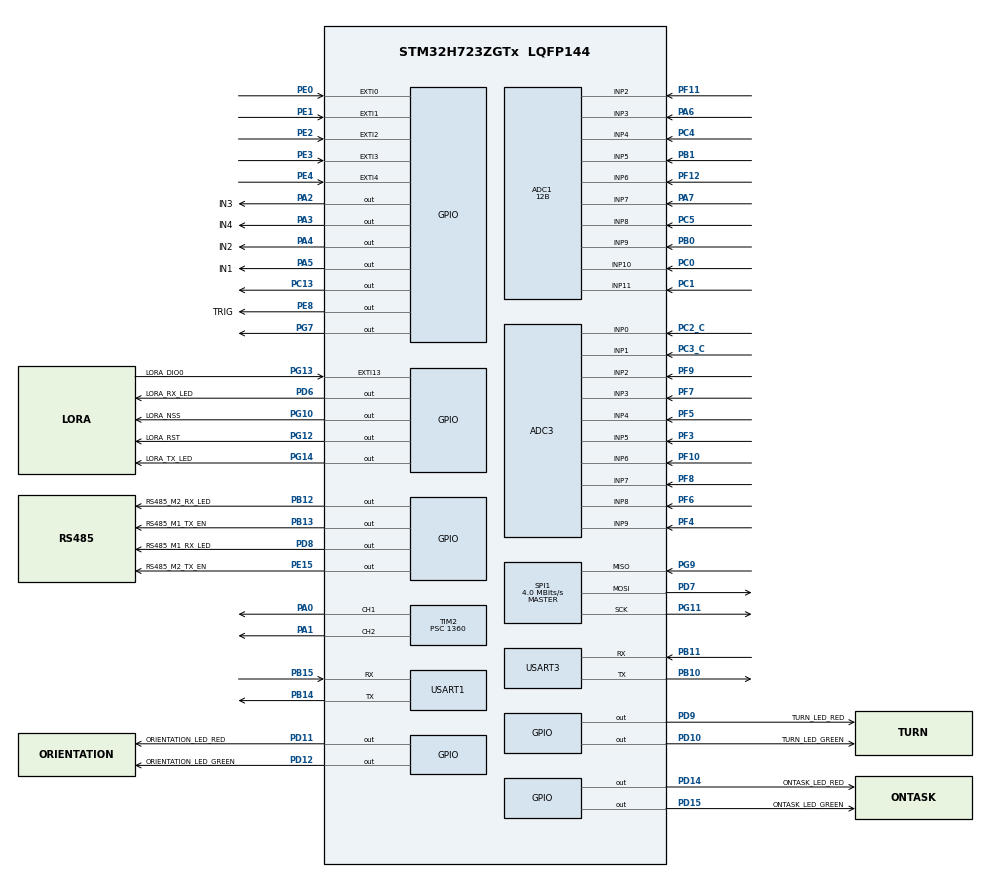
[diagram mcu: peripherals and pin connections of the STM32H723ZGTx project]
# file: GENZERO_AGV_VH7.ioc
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ADC1.Channel-0\#ChannelRegularConversion=ADC_CHANNEL_11
ADC1.Channel-1\#ChannelRegularConversion=ADC_CHANNEL_10
ADC1.Channel-2\#ChannelRegularConversion=ADC_CHANNEL_9
ADC1.Channel-3\#ChannelRegularConversion=ADC_CHANNEL_8
ADC1.Channel-4\#ChannelRegularConversion=ADC_CHANNEL_7
ADC1.Channel-5\#ChannelRegularConversion=ADC_CHANNEL_6
ADC1.Channel-6\#ChannelRegularConversion=ADC_CHANNEL_5
ADC1.Channel-7\#ChannelRegularConversion=ADC_CHANNEL_4
ADC1.Channel-8\#ChannelRegularConversion=ADC_CHANNEL_3
ADC1.Channel-9\#ChannelRegularConversion=ADC_CHANNEL_2
ADC1.ClockPrescaler=ADC_CLOCK_ASYNC_DIV1
ADC1.ClockPrescalerADC3=ADC_CLOCK_ASYNC_DIV1
ADC1.ContinuousConvMode=ENABLE
ADC1.ConversionDataManagement=ADC_CONVERSIONDATA_DMA_CIRCULAR
ADC1.EOCSelection=ADC_EOC_SINGLE_CONV
ADC1.NbrOfConversion=10
ADC1.NbrOfConversionFlag=1
ADC1.OffsetNumber-0\#ChannelRegularConversion=ADC_OFFSET_NONE
ADC1.OffsetNumber-1\#ChannelRegularConversion=ADC_OFFSET_NONE
ADC1.OffsetNumber-2\#ChannelRegularConversion=ADC_OFFSET_NONE
ADC1.OffsetNumber-3\#ChannelRegularConversion=ADC_OFFSET_NONE
ADC1.OffsetNumber-4\#ChannelRegularConversion=ADC_OFFSET_NONE
ADC1.OffsetNumber-5\#ChannelRegularConversion=ADC_OFFSET_NONE
ADC1.OffsetNumber-6\#ChannelRegularConversion=ADC_OFFSET_NONE
ADC1.OffsetNumber-7\#ChannelRegularConversion=ADC_OFFSET_NONE
ADC1.OffsetNumber-8\#ChannelRegularConversion=ADC_OFFSET_NONE
ADC1.OffsetNumber-9\#ChannelRegularConversion=ADC_OFFSET_NONE
ADC1.OffsetSignedSaturation-0\#ChannelRegularConversion=DISABLE
ADC1.Overrun=ADC_OVR_DATA_OVERWRITTEN
ADC1.Rank-0\#ChannelRegularConversion=1
ADC1.Rank-1\#ChannelRegularConversion=2
ADC1.Rank-2\#ChannelRegularConversion=3
ADC1.Rank-3\#ChannelRegularConversion=4
ADC1.Rank-4\#ChannelRegularConversion=5
ADC1.Rank-5\#ChannelRegularConversion=6
ADC1.Rank-6\#ChannelRegularConversion=7
ADC1.Rank-7\#ChannelRegularConversion=8
ADC1.Rank-8\#ChannelRegularConversion=9
ADC1.Rank-9\#ChannelRegularConversion=10
ADC1.Resolution=ADC_RESOLUTION_12B
ADC1.SamplingTime-0\#ChannelRegularConversion=ADC_SAMPLETIME_64CYCLES_5
ADC1.SamplingTime-1\#ChannelRegularConversion=ADC_SAMPLETIME_64CYCLES_5
ADC1.SamplingTime-2\#ChannelRegularConversion=ADC_SAMPLETIME_64CYCLES_5
ADC1.SamplingTime-3\#ChannelRegularConversion=ADC_SAMPLETIME_64CYCLES_5
ADC1.SamplingTime-4\#ChannelRegularConversion=ADC_SAMPLETIME_64CYCLES_5
ADC1.SamplingTime-5\#ChannelRegularConversion=ADC_SAMPLETIME_64CYCLES_5
ADC1.SamplingTime-6\#ChannelRegularConversion=ADC_SAMPLETIME_64CYCLES_5
ADC1.SamplingTime-7\#ChannelRegularConversion=ADC_SAMPLETIME_64CYCLES_5
ADC1.SamplingTime-8\#ChannelRegularConversion=ADC_SAMPLETIME_64CYCLES_5
ADC1.SamplingTime-9\#ChannelRegularConversion=ADC_SAMPLETIME_64CYCLES_5
ADC1.master=1
ADC3.Channel-0\#ChannelRegularConversion=ADC_CHANNEL_9
ADC3.Channel-1\#ChannelRegularConversion=ADC_CHANNEL_8
ADC3.Channel-2\#ChannelRegularConversion=ADC_CHANNEL_7
ADC3.Channel-3\#ChannelRegularConversion=ADC_CHANNEL_6
ADC3.Channel-4\#ChannelRegularConversion=ADC_CHANNEL_5
ADC3.Channel-5\#ChannelRegularConversion=ADC_CHANNEL_4
ADC3.Channel-6\#ChannelRegularConversion=ADC_CHANNEL_3
ADC3.Channel-7\#ChannelRegularConversion=ADC_CHANNEL_2
ADC3.Channel-8\#ChannelRegularConversion=ADC_CHANNEL_1
ADC3.Channel-9\#ChannelRegularConversion=ADC_CHANNEL_0
ADC3.ClockPrescaler=ADC_CLOCK_ASYNC_DIV1
ADC3.ClockPrescalerADC3=ADC_CLOCK_ASYNC_DIV1
ADC3.ContinuousConvMode=ENABLE
ADC3.ConversionDataManagement=ADC_CONVERSIONDATA_DMA_CIRCULAR
ADC3.DMAContinuousRequests=ENABLE
ADC3.EOCSelection=ADC_EOC_SINGLE_CONV
ADC3.NbrOfConversion=10
ADC3.NbrOfConversionFlag=1
ADC3.OffsetNumber-0\#ChannelRegularConversion=ADC_OFFSET_NONE
ADC3.OffsetNumber-1\#ChannelRegularConversion=ADC_OFFSET_NONE
ADC3.OffsetNumber-2\#ChannelRegularConversion=ADC_OFFSET_NONE
ADC3.OffsetNumber-3\#ChannelRegularConversion=ADC_OFFSET_NONE
ADC3.OffsetNumber-4\#ChannelRegularConversion=ADC_OFFSET_NONE
ADC3.OffsetNumber-5\#ChannelRegularConversion=ADC_OFFSET_NONE
ADC3.OffsetNumber-6\#ChannelRegularConversion=ADC_OFFSET_NONE
ADC3.OffsetNumber-7\#ChannelRegularConversion=ADC_OFFSET_NONE
ADC3.OffsetNumber-8\#ChannelRegularConversion=ADC_OFFSET_NONE
ADC3.OffsetNumber-9\#ChannelRegularConversion=ADC_OFFSET_NONE
ADC3.OffsetSign-0\#ChannelRegularConversion=ADC3_OFFSET_SIGN_NEGATIVE
ADC3.OffsetSign-1\#ChannelRegularConversion=ADC3_OFFSET_SIGN_NEGATIVE
ADC3.OffsetSign-2\#ChannelRegularConversion=ADC3_OFFSET_SIGN_NEGATIVE
ADC3.OffsetSign-3\#ChannelRegularConversion=ADC3_OFFSET_SIGN_NEGATIVE
ADC3.OffsetSign-4\#ChannelRegularConversion=ADC3_OFFSET_SIGN_NEGATIVE
ADC3.OffsetSign-5\#ChannelRegularConversion=ADC3_OFFSET_SIGN_NEGATIVE
ADC3.OffsetSign-6\#ChannelRegularConversion=ADC3_OFFSET_SIGN_NEGATIVE
ADC3.OffsetSign-7\#ChannelRegularConversion=ADC3_OFFSET_SIGN_NEGATIVE
ADC3.OffsetSign-8\#ChannelRegularConversion=ADC3_OFFSET_SIGN_NEGATIVE
ADC3.OffsetSign-9\#ChannelRegularConversion=ADC3_OFFSET_SIGN_NEGATIVE
ADC3.Overrun=ADC_OVR_DATA_OVERWRITTEN
ADC3.Rank-0\#ChannelRegularConversion=1
ADC3.Rank-1\#ChannelRegularConversion=2
ADC3.Rank-2\#ChannelRegularConversion=3
ADC3.Rank-3\#ChannelRegularConversion=4
ADC3.Rank-4\#ChannelRegularConversion=5
ADC3.Rank-5\#ChannelRegularConversion=6
ADC3.Rank-6\#ChannelRegularConversion=7
ADC3.Rank-7\#ChannelRegularConversion=8
ADC3.Rank-8\#ChannelRegularConversion=9
ADC3.Rank-9\#ChannelRegularConversion=10
ADC3.SamplingTime-0\#ChannelRegularConversion=ADC3_SAMPLETIME_92CYCLES_5
ADC3.SamplingTime-1\#ChannelRegularConversion=ADC3_SAMPLETIME_92CYCLES_5
ADC3.SamplingTime-2\#ChannelRegularConversion=ADC3_SAMPLETIME_92CYCLES_5
ADC3.SamplingTime-3\#ChannelRegularConversion=ADC3_SAMPLETIME_92CYCLES_5
ADC3.SamplingTime-4\#ChannelRegularConversion=ADC3_SAMPLETIME_92CYCLES_5
ADC3.SamplingTime-5\#ChannelRegularConversion=ADC3_SAMPLETIME_92CYCLES_5
ADC3.SamplingTime-6\#ChannelRegularConversion=ADC3_SAMPLETIME_92CYCLES_5
ADC3.SamplingTime-7\#ChannelRegularConversion=ADC3_SAMPLETIME_92CYCLES_5
ADC3.SamplingTime-8\#ChannelRegularConversion=ADC3_SAMPLETIME_92CYCLES_5
ADC3.SamplingTime-9\#ChannelRegularConversion=ADC3_SAMPLETIME_92CYCLES_5
Dma.ADC1.0.Direction=DMA_PERIPH_TO_MEMORY
Dma.ADC1.0.EventEnable=DISABLE
Dma.ADC1.0.FIFOMode=DMA_FIFOMODE_DISABLE
Dma.ADC1.0.Instance=DMA1_Stream0
Dma.ADC1.0.MemDataAlignment=DMA_MDATAALIGN_HALFWORD
Dma.ADC1.0.MemInc=DMA_MINC_ENABLE
Dma.ADC1.0.Mode=DMA_CIRCULAR
Dma.ADC1.0.PeriphDataAlignment=DMA_PDATAALIGN_HALFWORD
Dma.ADC1.0.PeriphInc=DMA_PINC_DISABLE
Dma.ADC1.0.Polarity=HAL_DMAMUX_REQ_GEN_RISING
Dma.ADC1.0.Priority=DMA_PRIORITY_HIGH
Dma.ADC1.0.RequestNumber=1
Dma.ADC1.0.SignalID=NONE
Dma.ADC1.0.SyncEnable=DISABLE
Dma.ADC1.0.SyncPolarity=HAL_DMAMUX_SYNC_NO_EVENT
Dma.ADC1.0.SyncRequestNumber=1
Dma.ADC1.0.SyncSignalID=NONE
Dma.ADC3.1.Direction=DMA_PERIPH_TO_MEMORY
Dma.ADC3.1.EventEnable=DISABLE
Dma.ADC3.1.FIFOMode=DMA_FIFOMODE_DISABLE
Dma.ADC3.1.Instance=DMA1_Stream1
Dma.ADC3.1.MemDataAlignment=DMA_MDATAALIGN_HALFWORD
Dma.ADC3.1.MemInc=DMA_MINC_ENABLE
Dma.ADC3.1.Mode=DMA_CIRCULAR
Dma.ADC3.1.PeriphDataAlignment=DMA_PDATAALIGN_HALFWORD
Dma.ADC3.1.PeriphInc=DMA_PINC_DISABLE
Dma.ADC3.1.Polarity=HAL_DMAMUX_REQ_GEN_RISING
Dma.ADC3.1.Priority=DMA_PRIORITY_HIGH
Dma.ADC3.1.RequestNumber=1
Dma.ADC3.1.SignalID=NONE
Dma.ADC3.1.SyncEnable=DISABLE
Dma.ADC3.1.SyncPolarity=HAL_DMAMUX_SYNC_NO_EVENT
Dma.ADC3.1.SyncRequestNumber=1
Dma.ADC3.1.SyncSignalID=NONE
Dma.Request0=ADC1
Dma.Request1=ADC3
Mcu.Family=STM32H7
Mcu.Name=STM32H723ZGTx
Mcu.Package=LQFP144
NVIC.ADC3_IRQn=true\:0\:0\:false\:false\:true\:true\:true\:true
NVIC.ADC_IRQn=true\:0\:0\:false\:false\:true\:true\:true\:true
NVIC.DMA1_Stream0_IRQn=true\:0\:0\:false\:false\:true\:false\:true\:true
NVIC.DMA1_Stream1_IRQn=true\:0\:0\:false\:false\:true\:false\:true\:true
NVIC.EXTI0_IRQn=true\:0\:0\:false\:false\:true\:true\:true\:true
NVIC.EXTI15_10_IRQn=true\:0\:0\:false\:false\:true\:true\:true\:true
NVIC.EXTI1_IRQn=true\:0\:0\:false\:false\:true\:true\:true\:true
NVIC.EXTI2_IRQn=true\:0\:0\:false\:false\:true\:true\:true\:true
NVIC.EXTI3_IRQn=true\:0\:0\:false\:false\:true\:true\:true\:true
NVIC.PriorityGroup=NVIC_PRIORITYGROUP_4
NVIC.TIM2_IRQn=true\:0\:0\:false\:false\:true\:true\:true\:true
NVIC.TIM3_IRQn=true\:0\:0\:false\:false\:true\:true\:true\:true
NVIC.TIM4_IRQn=true\:0\:0\:false\:false\:true\:true\:true\:true
NVIC.USART1_IRQn=true\:0\:0\:true\:false\:true\:true\:true\:true
NVIC.USART3_IRQn=true\:0\:0\:false\:false\:true\:true\:true\:true
PA0.Signal=S_TIM2_CH1_ETR
PA1.Signal=S_TIM2_CH2
PA2.GPIO_Label=IN3
PA2.Signal=GPIO_Output
PA3.GPIO_Label=IN4
PA3.Signal=GPIO_Output
PA4.GPIO_Label=IN2
PA4.Signal=GPIO_Output
PA5.GPIO_Label=IN1
PA5.Signal=GPIO_Output
PA6.Signal=ADCx_INP3
PA7.Signal=ADCx_INP7
PB0.Signal=ADCx_INP9
PB1.Signal=ADCx_INP5
PB10.Mode=Asynchronous
PB10.Signal=USART3_TX
PB11.Mode=Asynchronous
PB11.Signal=USART3_RX
PB12.GPIO_Label=RS485_M2_RX_LED
PB12.Signal=GPIO_Output
PB13.GPIO_Label=RS485_M1_TX_EN
PB13.GPIO_Speed=GPIO_SPEED_FREQ_HIGH
PB13.Signal=GPIO_Output
PB14.GPIO_Speed=GPIO_SPEED_FREQ_VERY_HIGH
PB14.Mode=Asynchronous
PB14.Signal=USART1_TX
PB15.GPIO_Speed=GPIO_SPEED_FREQ_VERY_HIGH
PB15.Mode=Asynchronous
PB15.Signal=USART1_RX
PC0.Signal=ADCx_INP10
PC1.Signal=ADCx_INP11
PC13.Signal=GPIO_Output
PC2_C.Mode=IN0-Single-Ended
PC2_C.Signal=ADC3_INP0
PC3_C.Mode=IN1-Single-Ended
PC3_C.Signal=ADC3_INP1
PC4.Signal=ADCx_INP4
PC5.Signal=ADCx_INP8
PD10.GPIO_Label=TURN_LED_GREEN
PD10.Signal=GPIO_Output
PD11.GPIO_Label=ORIENTATION_LED_RED
PD11.Signal=GPIO_Output
PD12.GPIO_Label=ORIENTATION_LED_GREEN
PD12.Signal=GPIO_Output
PD14.GPIO_Label=ONTASK_LED_RED
PD14.Signal=GPIO_Output
PD15.GPIO_Label=ONTASK_LED_GREEN
PD15.Signal=GPIO_Output
PD6.GPIO_Label=LORA_RX_LED
PD6.PinState=GPIO_PIN_SET
PD6.Signal=GPIO_Output
PD7.Mode=Full_Duplex_Master
PD7.Signal=SPI1_MOSI
PD8.GPIO_Label=RS485_M1_RX_LED
PD8.Signal=GPIO_Output
PD9.GPIO_Label=TURN_LED_RED
PD9.Signal=GPIO_Output
PE0.GPIO_ModeDefaultEXTI=GPIO_MODE_IT_FALLING
PE0.Signal=GPXTI0
PE1.GPIO_ModeDefaultEXTI=GPIO_MODE_IT_FALLING
PE1.Signal=GPXTI1
PE15.GPIO_Label=RS485_M2_TX_EN
PE15.GPIO_Speed=GPIO_SPEED_FREQ_HIGH
PE15.Signal=GPIO_Output
PE2.GPIO_ModeDefaultEXTI=GPIO_MODE_IT_FALLING
PE2.Signal=GPXTI2
PE3.GPIO_ModeDefaultEXTI=GPIO_MODE_IT_FALLING
PE3.Signal=GPXTI3
PE4.GPIO_ModeDefaultEXTI=GPIO_MODE_IT_FALLING
PE4.Signal=GPXTI4
PE8.GPIO_Label=TRIG
PE8.GPIO_PuPd=GPIO_PULLDOWN
PE8.GPIO_Speed=GPIO_SPEED_FREQ_HIGH
PE8.Signal=GPIO_Output
PF10.Mode=IN6-Single-Ended
PF10.Signal=ADC3_INP6
PF11.Mode=IN2-Single-Ended
PF11.Signal=ADC1_INP2
PF12.Mode=IN6-Single-Ended
PF12.Signal=ADC1_INP6
PF3.Mode=IN5-Single-Ended
PF3.Signal=ADC3_INP5
PF4.Mode=IN9-Single-Ended
PF4.Signal=ADC3_INP9
PF5.Mode=IN4-Single-Ended
PF5.Signal=ADC3_INP4
PF6.Mode=IN8-Single-Ended
PF6.Signal=ADC3_INP8
PF7.Mode=IN3-Single-Ended
PF7.Signal=ADC3_INP3
PF8.Mode=IN7-Single-Ended
PF8.Signal=ADC3_INP7
PF9.Mode=IN2-Single-Ended
PF9.Signal=ADC3_INP2
PG10.GPIO_Label=LORA_NSS
PG10.PinState=GPIO_PIN_SET
PG10.Signal=GPIO_Output
PG11.Mode=Full_Duplex_Master
PG11.Signal=SPI1_SCK
PG12.GPIO_Label=LORA_RST
PG12.PinState=GPIO_PIN_SET
PG12.Signal=GPIO_Output
PG13.GPIO_Label=LORA_DIO0
PG13.Signal=GPXTI13
PG14.GPIO_Label=LORA_TX_LED
PG14.Signal=GPIO_Output
PG7.Signal=GPIO_Output
PG9.Mode=Full_Duplex_Master
PG9.Signal=SPI1_MISO
PH0-OSC_IN.Mode=HSE-External-Oscillator
PH0-OSC_IN.Signal=RCC_OSC_IN
PH1-OSC_OUT.Mode=HSE-External-Oscillator
PH1-OSC_OUT.Signal=RCC_OSC_OUT
ProjectManager.HeapSize=0x200
ProjectManager.StackSize=0x400
ProjectManager.TargetToolchain=STM32CubeIDE
RCC.ADCFreq_Value=96000671.38671875
RCC.APB1Freq_Value=137500000
RCC.APB2Freq_Value=137500000
RCC.APB3Freq_Value=137500000
RCC.APB4Freq_Value=137500000
RCC.CortexFreq_Value=550000000
RCC.D1PPRE=RCC_APB3_DIV2
RCC.D2PPRE1=RCC_APB1_DIV2
RCC.D2PPRE2=RCC_APB2_DIV2
RCC.D3PPRE=RCC_APB4_DIV2
RCC.DIVM1=2
RCC.DIVM2=2
RCC.DIVN1=44
RCC.DIVN2=15
RCC.DIVP1=1
RCC.DIVQ1=3
RCC.HCLKFreq_Value=275000000
RCC.HPRE=RCC_HCLK_DIV2
RCC.PLL2FRACN=2950
RCC.PLL3FRACN=0
RCC.PLLFRACN=0
RCC.PLLSourceVirtual=RCC_PLLSOURCE_HSE
RCC.SPI123CLockSelection=RCC_SPI123CLKSOURCE_CLKP
RCC.SYSCLKFreq_VALUE=550000000
RCC.SYSCLKSource=RCC_SYSCLKSOURCE_PLLCLK
RCC.USBFreq_Value=183333333.33333334
SH.ADCx_INP10.0=ADC1_INP10,IN10-Single-Ended
SH.ADCx_INP11.0=ADC1_INP11,IN11-Single-Ended
SH.ADCx_INP3.0=ADC1_INP3,IN3-Single-Ended
SH.ADCx_INP4.0=ADC1_INP4,IN4-Single-Ended
SH.ADCx_INP5.0=ADC1_INP5,IN5-Single-Ended
SH.ADCx_INP7.0=ADC1_INP7,IN7-Single-Ended
SH.ADCx_INP8.0=ADC1_INP8,IN8-Single-Ended
SH.ADCx_INP9.0=ADC1_INP9,IN9-Single-Ended
SH.S_TIM2_CH1_ETR.0=TIM2_CH1,PWM Generation1 CH1
SH.S_TIM2_CH2.0=TIM2_CH2,PWM Generation2 CH2
SPI1.BaudRatePrescaler=SPI_BAUDRATEPRESCALER_16
SPI1.CalculateBaudRate=4.0 MBits/s
SPI1.DataSize=SPI_DATASIZE_8BIT
SPI1.Direction=SPI_DIRECTION_2LINES
SPI1.Mode=SPI_MODE_MASTER
SPI1.VirtualType=VM_MASTER
TIM2.AutoReloadPreload=TIM_AUTORELOAD_PRELOAD_ENABLE
TIM2.Channel-PWM\ Generation1\ CH1=TIM_CHANNEL_1
TIM2.Channel-PWM\ Generation2\ CH2=TIM_CHANNEL_2
TIM2.ClockDivision=TIM_CLOCKDIVISION_DIV1
TIM2.OC1Preload_PWM=DISABLE
TIM2.OC2Preload_PWM=DISABLE
TIM2.OCFastMode_PWM-PWM\ Generation1\ CH1=TIM_OCFAST_DISABLE
TIM2.OCFastMode_PWM-PWM\ Generation2\ CH2=TIM_OCFAST_DISABLE
TIM2.Period=100
TIM2.Prescaler=1360
TIM3.AutoReloadPreload=TIM_AUTORELOAD_PRELOAD_ENABLE
TIM3.Period=55000-1
TIM3.Prescaler=500-1
TIM4.AutoReloadPreload=TIM_AUTORELOAD_PRELOAD_ENABLE
TIM4.Period=55000-1
TIM4.Prescaler=500-1
USART1.ClockPrescaler=PRESCALER_DIV1
USART1.VirtualMode-Asynchronous=VM_ASYNC
USART3.VirtualMode-Asynchronous=VM_ASYNC
VP_MEMORYMAP_VS_MEMORYMAP.Mode=CurAppReg
VP_TIM3_VS_ClockSourceINT.Mode=Internal
VP_TIM4_VS_ClockSourceINT.Mode=Internal
board=custom

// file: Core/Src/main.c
/* USER CODE BEGIN Header */
/**
  ******************************************************************************
  * @file           : main.c
  * @brief          : Main program body
  ******************************************************************************
  * @attention
  *
  * Copyright (c) 2024 STMicroelectronics.
  * All rights reserved.
  *
  * This software is licensed under terms that can be found in the LICENSE file
  * in the root directory of this software component.
  * If no LICENSE file comes with this software, it is provided AS-IS.
  *
  ******************************************************************************

	GIT BRANCH: TEST TWO

  */
/* USER CODE END Header */
#include "main.h"

/* USER CODE BEGIN Includes */

#include "modbus_crc.h"
#include "line_sensor.h"
#include "LoRa.h"
#include "rs485_driver.h"

/* USER CODE END Includes */

ADC_HandleTypeDef hadc1;
ADC_HandleTypeDef hadc3;
DMA_HandleTypeDef hdma_adc1;
DMA_HandleTypeDef hdma_adc3;

SPI_HandleTypeDef hspi1;

TIM_HandleTypeDef htim2;
TIM_HandleTypeDef htim3;
TIM_HandleTypeDef htim4;

UART_HandleTypeDef huart1;
UART_HandleTypeDef huart3;

/* USER CODE BEGIN PV */

// #### RS485 ####

uint8_t rs485_m1_RxData[16];
uint8_t rs485_m1_TxData[8];

uint8_t rs485_m2_RxData[16];
uint8_t rs485_m2_TxData[8];

uint8_t rs485_m1_isbusy = 0;
uint8_t rs485_m2_isbusy = 0;

uint16_t rs485_m1_FailCheck = 0;
uint16_t rs485_m2_FailCheck = 0;

uint16_t rs485_m1_last_FailCheck = 0;
uint16_t rs485_m2_last_FailCheck = 0;

uint8_t rs485_m1_connectivity = 0;
uint8_t rs485_m2_connectivity = 0;

uint16_t rs485_exc_time = 0;
uint32_t rs485_time1 = 0;
uint32_t rs485_time2 = 0;

rs485_driver m1_driver;
rs485_driver m2_driver;

uint8_t time_t1 = 0;
uint8_t time_t2 = 0;

const uint16_t mid_point = 4500;

// #### END RS485 ####

// -o-o-o-o-o-o-o-o-o-o-o-o-o-o-o-o-o-

// #### LINE SENSOR VARIABLES ####

#define line_sensor_front_total_channel 10
#define line_sensor_back_total_channel 10

#define max_rs485_speed 100

int line_sensor_front_read_line_old_value;
int line_sensor_back_read_line_old_value;

volatile uint16_t line_sensor_front_values_dma[line_sensor_front_total_channel];
volatile uint16_t line_sensor_back_values_dma[line_sensor_back_total_channel];

volatile uint16_t line_sensor_front_values_calibrated[line_sensor_front_total_channel];
volatile uint16_t line_sensor_back_values_calibrated[line_sensor_back_total_channel];

volatile uint8_t line_sensor_front_on_line_left_number, line_sensor_front_on_line_middle_number, line_sensor_front_on_line_right_number;
volatile uint8_t line_sensor_front_on_line_total_number;

volatile uint8_t line_sensor_back_on_line_left_number, line_sensor_back_on_line_middle_number, line_sensor_back_on_line_right_number;
volatile uint8_t line_sensor_back_on_line_total_number;

uint16_t line_sensor_front_max_sensor_vales[line_sensor_front_total_channel] = {4095, 4095, 4095, 4095, 4095, 4095, 4095, 4095, 4095, 4095};
uint16_t line_sensor_front_min_sensor_vales[line_sensor_front_total_channel] = {560, 550, 600, 540, 500, 530, 500, 500, 500, 500};

uint16_t line_sensor_back_max_sensor_vales[line_sensor_back_total_channel] = {4095, 4095, 4095, 4095, 4095, 4095, 2800, 4095, 2800, 4095};
uint16_t line_sensor_back_min_sensor_vales[line_sensor_back_total_channel] = {750, 800, 700, 700, 700, 700, 500, 700, 550, 600};

const uint8_t line_sensor_front_channel_number = sizeof(line_sensor_front_values_dma)/sizeof(line_sensor_front_values_dma[0]);
const uint8_t line_sensor_back_channel_number = sizeof(line_sensor_back_values_dma)/sizeof(line_sensor_back_values_dma[0]);

volatile uint16_t line_sensor_front_read_line_value;
volatile uint16_t line_sensor_back_read_line_value;

//uint8_t line_gap_disable = 0;

const uint16_t line_sensor_front_threshold = 600;
const uint16_t line_sensor_back_threshold = 600;

ir_array front_array;
ir_array back_array;

// #### END LINE SENSOR VARIABLES ####

// -o-o-o-o-o-o-o-o-o-o-o-o-o-o-o-o-o-

// #### AGV ORIENTATION VARIABLES ####

uint16_t agv_orientation = 0xF00F;

// #### END AGV ORIENTATION VARIABLES ####

// -o-o-o-o-o-o-o-o-o-o-o-o-o-o-o-o-o-

// #### DiSPLAY DATA AND BUTTON VARIABLES ####

uint8_t Tx_Data_Uart1[5];
uint8_t Rx_Data_Uart1[5];

// #### END DiSPLAY DATA AND BUTTON VARIABLES ####

// -o-o-o-o-o-o-o-o-o-o-o-o-o-o-o-o-o-

// #### PID and MOTOR SPEED VARIABLES ####

volatile float P, I, D;

float Kp = 0.013;
float Ki = 0;
float Kd = 0.32;

volatile float pid_last_error;
volatile float pid_error;
volatile float pid_motor_speed_change;

volatile uint16_t pid_motor_speed_A;
volatile uint16_t pid_motor_speed_B;
uint16_t pid_motor_base_speed = 60;

uint8_t agv_turn_count = 0;

uint8_t debug_oled[20];
// #### END PID and MOTOR SPEED VARIABLES ####

// -o-o-o-o-o-o-o-o-o-o-o-o-o-o-o-o-o-

// #### Task Completion Variables ####

uint16_t On_Task = 0xF00F;  // not on task = 0xF00F || on task = 0xF11F

uint8_t Station = 0;

uint8_t Current_Station = 0;
uint8_t Target_Station = 0;

uint8_t on_task_decisions[5] = {'L', 'L', 'L', 'L', 'L'};

uint16_t pid_motor_orientation;

// #### END Task Completion Variables ####

// -o-o-o-o-o-o-o-o-o-o-o-o-o-o-o-o-o-

// #### LORA ####

LoRa myLoRa;

uint16_t LoRa_stat = 0;

uint8_t LoraTxBuffer[128];
uint8_t LoraRxBuffer[128];

uint8_t lora_receive_toggle = 0;

// #### END LORA ####

//uint8_t uid[MIFARE_UID_MAX_LENGTH];
//int32_t uid_len = 0;
//uint8_t uid_version[10];
//PN532 pn532;
//uint8_t Station_id[5];

uint32_t IC_Val1 = 0;
uint32_t IC_Val2 = 0;
uint32_t Difference = 0;
uint8_t Is_First_Captured = 0;  // is the first value captured ?
uint8_t Distance  = 0;

//#define TRIG_PIN GPIO_PIN_8
//#define TRIG_PORT GPIOE

/* USER CODE END PV */

void SystemClock_Config(void);
void PeriphCommonClock_Config(void);
static void MX_GPIO_Init(void);
static void MX_DMA_Init(void);
static void MX_ADC1_Init(void);
static void MX_ADC3_Init(void);
static void MX_USART1_UART_Init(void);
static void MX_TIM2_Init(void);
static void MX_SPI1_Init(void);
static void MX_USART3_UART_Init(void);
static void MX_TIM3_Init(void);
static void MX_TIM4_Init(void);

/* USER CODE BEGIN 0 */

void PID_control(volatile uint16_t *line_position,
				          uint16_t *motor_orientation){

	pid_error = 4500 - *line_position;

	P = pid_error;
	//I = error + I;
	I = 0;
	D = pid_error - pid_last_error;
	pid_last_error = pid_error;

	pid_motor_speed_change = P*Kp + I*Ki + D*Kd;

	if(*motor_orientation == 0xF11F){
		pid_motor_speed_A = pid_motor_base_speed + pid_motor_speed_change;
		pid_motor_speed_B = pid_motor_base_speed - pid_motor_speed_change;
	}
	if(*motor_orientation == 0xF00F){
		pid_motor_speed_A = pid_motor_base_speed - pid_motor_speed_change;
		pid_motor_speed_B = pid_motor_base_speed + pid_motor_speed_change;
	}

	if(pid_motor_speed_A > max_rs485_speed){
		pid_motor_speed_A = max_rs485_speed;
	}
	if(pid_motor_speed_A < 0){
		pid_motor_speed_A = 0;
	}
	if(pid_motor_speed_B > max_rs485_speed){
		pid_motor_speed_B = max_rs485_speed;
	}
	if(pid_motor_speed_B < 0){
		pid_motor_speed_B = 0;
	}

}

void PID_control_line_gap(volatile uint16_t *line_position){

	pid_error = 4500 - *line_position;

	P = pid_error;
	//I = error + I;
	I = 0;
	D = pid_error - pid_last_error;
	pid_last_error = pid_error;

	pid_motor_speed_change = P*Kp + I*Ki + D*Kd;

	pid_motor_speed_A = pid_motor_base_speed + pid_motor_speed_change;
	pid_motor_speed_B = pid_motor_base_speed - pid_motor_speed_change;

	if(pid_motor_speed_A > max_rs485_speed){
		pid_motor_speed_A = max_rs485_speed;
	}
	if(pid_motor_speed_A < 0){
		pid_motor_speed_A = 0;
	}
	if(pid_motor_speed_B > max_rs485_speed){
		pid_motor_speed_B = max_rs485_speed;
	}
	if(pid_motor_speed_B < 0){
		pid_motor_speed_B = 0;
	}

}

void PID_Forward_Rotation(uint16_t enableA, uint16_t enableB, uint16_t *orientation){

	if(*orientation == 0xF11F){
//		//LEFT
//		HAL_GPIO_WritePin(IN1_GPIO_Port, IN1_Pin, GPIO_PIN_SET);
//		HAL_GPIO_WritePin(IN2_GPIO_Port, IN2_Pin, GPIO_PIN_RESET);
//
//		//RIGHT
//		HAL_GPIO_WritePin(IN3_GPIO_Port, IN3_Pin, GPIO_PIN_RESET);
//		HAL_GPIO_WritePin(IN4_GPIO_Port, IN4_Pin, GPIO_PIN_SET);
//
//		//Right
//		__HAL_TIM_SET_COMPARE(&htim2, TIM_CHANNEL_1, enableA);
//
//		//Left
//		__HAL_TIM_SET_COMPARE(&htim2, TIM_CHANNEL_2, enableB);

		rs485_set_speed(&m1_driver, enableB, 0);
		rs485_set_speed(&m2_driver, enableA, 1);
	}

	if(*orientation == 0xF00F){

//		//LEFT
//		HAL_GPIO_WritePin(IN1_GPIO_Port, IN1_Pin, GPIO_PIN_RESET);
//		HAL_GPIO_WritePin(IN2_GPIO_Port, IN2_Pin, GPIO_PIN_SET);
//
//		//RIGHT
//		HAL_GPIO_WritePin(IN3_GPIO_Port, IN3_Pin, GPIO_PIN_SET);
//		HAL_GPIO_WritePin(IN4_GPIO_Port, IN4_Pin, GPIO_PIN_RESET);
//
//		//Right
//		__HAL_TIM_SET_COMPARE(&htim2, TIM_CHANNEL_1, enableA);
//
//		//Left
//		__HAL_TIM_SET_COMPARE(&htim2, TIM_CHANNEL_2, enableB);

		rs485_set_speed(&m1_driver, enableA, 1);
		rs485_set_speed(&m2_driver, enableB, 0);

	}

}

void PID_Motor_Turn_Left(uint16_t _speed, uint16_t *orientation){
	if(*orientation == 0xF11F){
//		//LEFT
//		HAL_GPIO_WritePin(IN1_GPIO_Port, IN1_Pin, GPIO_PIN_SET);
//		HAL_GPIO_WritePin(IN2_GPIO_Port, IN2_Pin, GPIO_PIN_RESET);
//
//		//RIGHT
//		HAL_GPIO_WritePin(IN3_GPIO_Port, IN3_Pin, GPIO_PIN_SET);
//		HAL_GPIO_WritePin(IN4_GPIO_Port, IN4_Pin, GPIO_PIN_RESET);
//
//		//Right
//		__HAL_TIM_SET_COMPARE(&htim2, TIM_CHANNEL_1, _speed);
//
//		//Left
//		__HAL_TIM_SET_COMPARE(&htim2, TIM_CHANNEL_2, _speed);

		rs485_set_speed(&m1_driver, _speed, 0);
		rs485_set_speed(&m2_driver, _speed, 0);
	}

	if(*orientation == 0xF00F){

//		//LEFT
//		HAL_GPIO_WritePin(IN1_GPIO_Port, IN1_Pin, GPIO_PIN_SET);
//		HAL_GPIO_WritePin(IN2_GPIO_Port, IN2_Pin, GPIO_PIN_RESET);
//
//		//RIGHT
//		HAL_GPIO_WritePin(IN3_GPIO_Port, IN3_Pin, GPIO_PIN_SET);
//		HAL_GPIO_WritePin(IN4_GPIO_Port, IN4_Pin, GPIO_PIN_RESET);
//
//		//Right
//		__HAL_TIM_SET_COMPARE(&htim2, TIM_CHANNEL_1, _speed);
//
//		//Left
//		__HAL_TIM_SET_COMPARE(&htim2, TIM_CHANNEL_2, _speed);

		rs485_set_speed(&m1_driver, _speed, 0);
		rs485_set_speed(&m2_driver, _speed, 0);

	}
}

void PID_Motor_Turn_Right(uint16_t _speed, uint16_t *orientation){
	if(*orientation == 0xF11F){
//		//LEFT
//		HAL_GPIO_WritePin(IN1_GPIO_Port, IN1_Pin, GPIO_PIN_RESET);
//		HAL_GPIO_WritePin(IN2_GPIO_Port, IN2_Pin, GPIO_PIN_SET);
//
//		//RIGHT
//		HAL_GPIO_WritePin(IN3_GPIO_Port, IN3_Pin, GPIO_PIN_RESET);
//		HAL_GPIO_WritePin(IN4_GPIO_Port, IN4_Pin, GPIO_PIN_SET);
//
//		//Right
//		__HAL_TIM_SET_COMPARE(&htim2, TIM_CHANNEL_1, _speed);
//
//		//Left
//		__HAL_TIM_SET_COMPARE(&htim2, TIM_CHANNEL_2, _speed);

		rs485_set_speed(&m1_driver, _speed, 1);
		rs485_set_speed(&m2_driver, _speed, 1);
	}

	if(*orientation == 0xF00F){

//		//LEFT
//		HAL_GPIO_WritePin(IN1_GPIO_Port, IN1_Pin, GPIO_PIN_RESET);
//		HAL_GPIO_WritePin(IN2_GPIO_Port, IN2_Pin, GPIO_PIN_SET);
//
//		//RIGHT
//		HAL_GPIO_WritePin(IN3_GPIO_Port, IN3_Pin, GPIO_PIN_RESET);
//		HAL_GPIO_WritePin(IN4_GPIO_Port, IN4_Pin, GPIO_PIN_SET);
//
//		//Right
//		__HAL_TIM_SET_COMPARE(&htim2, TIM_CHANNEL_1, _speed);
//
//		//Left
//		__HAL_TIM_SET_COMPARE(&htim2, TIM_CHANNEL_2, _speed);

		rs485_set_speed(&m1_driver, _speed, 1);
		rs485_set_speed(&m2_driver, _speed, 1);

	}

}

void PID_Motor_All_Break(){
//	//LEFT
//	HAL_GPIO_WritePin(IN1_GPIO_Port, IN1_Pin, GPIO_PIN_RESET);
//	HAL_GPIO_WritePin(IN2_GPIO_Port, IN2_Pin, GPIO_PIN_RESET);
//
//	//RIGHT
//	HAL_GPIO_WritePin(IN3_GPIO_Port, IN3_Pin, GPIO_PIN_RESET);
//	HAL_GPIO_WritePin(IN4_GPIO_Port, IN4_Pin, GPIO_PIN_RESET);
//
//	//Right
//	__HAL_TIM_SET_COMPARE(&htim2, TIM_CHANNEL_1, 0);
//
//	//Left
//	__HAL_TIM_SET_COMPARE(&htim2, TIM_CHANNEL_2, 0);

//	motor_enable_velocity_mode(0x01);
//	motor_enable_velocity_mode(0x02);
	rs485_set_speed(&m1_driver, 0, 1);
	rs485_set_speed(&m2_driver, 0, 1);

}

void AGV_waiting(){
	if(Target_Station == Current_Station){
		On_Task = 0xF00F;
		if(Target_Station != Station){
			Target_Station = Station;
			if(Current_Station == 0){
				if(Target_Station == 1){
					on_task_decisions[0] = 'L';
					on_task_decisions[1] = 'L';
					on_task_decisions[2] = 'E';
					on_task_decisions[3] = 'E';
					on_task_decisions[4] = 'E';
				}
				if(Target_Station == 2){
					on_task_decisions[0] = 'L';
					on_task_decisions[1] = 'F';
					on_task_decisions[2] = 'L';
					on_task_decisions[3] = 'E';
					on_task_decisions[4] = 'E';
				}
				if(Target_Station == 3){
					on_task_decisions[0] = 'L';
					on_task_decisions[1] = 'F';
					on_task_decisions[2] = 'F';
					on_task_decisions[3] = 'L';
					on_task_decisions[4] = 'E';
				}
			}

			if(Current_Station == 1){
				if(Target_Station == 0){
					on_task_decisions[0] = 'R';
					on_task_decisions[1] = 'R';
					on_task_decisions[2] = 'E';
					on_task_decisions[3] = 'E';
					on_task_decisions[4] = 'E';
				}
				if(Target_Station == 2){
					on_task_decisions[0] = 'L';
					on_task_decisions[1] = 'L';
					on_task_decisions[2] = 'E';
					on_task_decisions[3] = 'E';
					on_task_decisions[4] = 'E';
				}
				if(Target_Station == 3){
					on_task_decisions[0] = 'L';
					on_task_decisions[1] = 'F';
					on_task_decisions[2] = 'L';
					on_task_decisions[3] = 'E';
					on_task_decisions[4] = 'E';
				}
			}

			if(Current_Station == 2){
				if(Target_Station == 0){
					on_task_decisions[0] = 'R';
					on_task_decisions[1] = 'F';
					on_task_decisions[2] = 'R';
					on_task_decisions[3] = 'E';
					on_task_decisions[4] = 'E';
				}
				if(Target_Station == 1){
					on_task_decisions[0] = 'R';
					on_task_decisions[1] = 'R';
					on_task_decisions[2] = 'E';
					on_task_decisions[3] = 'E';
					on_task_decisions[4] = 'E';
				}
				if(Target_Station == 3){
					on_task_decisions[0] = 'L';
					on_task_decisions[1] = 'L';
					on_task_decisions[2] = 'E';
					on_task_decisions[3] = 'E';
					on_task_decisions[4] = 'E';
				}
			}

			if(Current_Station == 3){
				if(Target_Station == 0){
					on_task_decisions[0] = 'R';
					on_task_decisions[1] = 'F';
					on_task_decisions[2] = 'F';
					on_task_decisions[3] = 'R';
					on_task_decisions[4] = 'E';
				}
				if(Target_Station == 1){
					on_task_decisions[0] = 'R';
					on_task_decisions[1] = 'F';
					on_task_decisions[2] = 'R';
					on_task_decisions[3] = 'E';
					on_task_decisions[4] = 'E';
				}
				if(Target_Station == 2){
					on_task_decisions[0] = 'R';
					on_task_decisions[1] = 'R';
					on_task_decisions[2] = 'E';
					on_task_decisions[3] = 'E';
					on_task_decisions[4] = 'E';
				}
			}

		}
	}
	if(Target_Station != Current_Station){
		On_Task = 0xF11F;
	}
}

//void AGV_Turn_Detection_Completion(volatile uint16_t *sensor_calibrated_values,
//								   volatile uint8_t  *sensor_middle_on_line_number,
//								   volatile uint8_t  *sensor_total_on_line_number,
//								   	   	   	uint8_t  *decision_array,
//											uint16_t *orientation){
//#define white_detection_thresh_hold 500
//#define black_detection_thresh_hold 500
//#define sensor_mid_on_line_thresh_hold 1
//#define first_timer_buffer 800
//#define second_timer_buffer 300
//#define skip_turn_timer_buffer 200
//#define base_speed 50
//
//	uint8_t _turn_decide = 0;
//
//	if((((sensor_calibrated_values[8] > black_detection_thresh_hold) && (sensor_calibrated_values[9] > black_detection_thresh_hold)) ||
//	   ((sensor_calibrated_values[0] > black_detection_thresh_hold) && (sensor_calibrated_values[1] > black_detection_thresh_hold))) && (*sensor_total_on_line_number >= 8)){
////		if((*sensor_middle_on_line_number >= 5) || (*sensor_middle_on_line_number == 6)){
//
//
//			HAL_GPIO_TogglePin(GPIOG, GPIO_PIN_7);
//
////			PID_Forward_Rotation(base_speed, base_speed, orientation);
////			HAL_Delay(100);
//
//			agv_turn_count += 1;
//
//			PID_Motor_All_Break();
//
//			HAL_Delay(2000);
//
//			if(decision_array[agv_turn_count - 1] == 'E'){
//
//
//
//
////								  Line_Sensor_Calculation(line_sensor_front_values_dma,
////														  line_sensor_front_values_calibrated,
////														  line_sensor_front_max_sensor_vales,
////														  line_sensor_front_min_sensor_vales,
////														 &line_sensor_front_on_line_middle_number,
////														 &line_sensor_front_on_line_total_number,
////														  line_sensor_front_trigger_threshhold,
////														  line_sensor_front_total_channel,
////														 &line_sensor_front_read_line_value);
////
////								  Line_Sensor_Calculation(line_sensor_back_values_dma,
////														  line_sensor_back_values_calibrated,
////														  line_sensor_back_max_sensor_vales,
////														  line_sensor_back_min_sensor_vales,
////														 &line_sensor_back_on_line_middle_number,
////														 &line_sensor_back_on_line_total_number,
////														  line_sensor_back_trigger_threshhold,
////														  line_sensor_back_total_channel,
////														 &line_sensor_back_read_line_value);
////
////								  if(line_sensor_back_on_line_total_number >= 9){
////									  agv_orientation = 0xF00F;
////								  }
////								  if(line_sensor_front_on_line_total_number >= 9){
////									  agv_orientation = 0xF11F;
////								  }
//
//
//								PID_Motor_All_Break();
//
//
//
//								Current_Station = Target_Station;
//
//								On_Task = 0xF00F;
//
//								if(agv_orientation == 0xF00F){
//									agv_orientation = 0xF11F;
//								}
//								else if(agv_orientation == 0xF11F){
//									agv_orientation = 0xF00F;
//								}
//
//								_turn_decide = 0;
//								agv_turn_count = 0;
//
//
//			}
//			else if(decision_array[agv_turn_count - 1] != 'E'){
//
//				//line_gap_disable = 1;
//
//				PID_Forward_Rotation(base_speed, base_speed, orientation);
//				HAL_Delay(first_timer_buffer);
//				PID_Motor_All_Break();
//
//				HAL_Delay(1000);
//
//				if(decision_array[agv_turn_count - 1] == 'R'){
//
//					PID_Motor_Turn_Right(base_speed, orientation);
//					HAL_Delay(second_timer_buffer);
//					PID_Motor_All_Break();
//
//					HAL_Delay(1000);
//
//					_turn_decide = 'R';
//				}
//				if(decision_array[agv_turn_count - 1] == 'L'){
//
//					PID_Motor_Turn_Left(base_speed, orientation);
//					HAL_Delay(second_timer_buffer);
//					PID_Motor_All_Break();
//
//					HAL_Delay(1000);
//
//					_turn_decide = 'L';
//				}
//				if(decision_array[agv_turn_count - 1] == 'F'){
//
//					PID_Forward_Rotation(base_speed, base_speed, orientation);
//					HAL_Delay(skip_turn_timer_buffer);
//					_turn_decide = 0;
//				}
//			}
//
//	}
//
//	if((sensor_calibrated_values[8] < white_detection_thresh_hold) && (sensor_calibrated_values[9] < white_detection_thresh_hold) &&
//			(sensor_calibrated_values[0] > black_detection_thresh_hold) && (sensor_calibrated_values[1] > black_detection_thresh_hold)){
//			if((*sensor_middle_on_line_number >= 3) && (*sensor_middle_on_line_number < 6)){
//
//				//line_gap_disable = 1;
//
//			PID_Forward_Rotation(base_speed, base_speed, orientation);
//			HAL_Delay(first_timer_buffer);
//			PID_Motor_All_Break();
//
//			HAL_Delay(1000);
//
//			agv_turn_count += 1;
//
//			HAL_GPIO_TogglePin(GPIOG, GPIO_PIN_7);
//
//			if(decision_array[agv_turn_count - 1] == 'L'){
//
//				PID_Motor_Turn_Left(base_speed, orientation);
//				HAL_Delay(second_timer_buffer);
//				PID_Motor_All_Break();
//
//				HAL_Delay(1000);
//
//				_turn_decide = 'L';
//			}
//			if(decision_array[agv_turn_count - 1] == 'F'){
//
//				PID_Forward_Rotation(base_speed, base_speed, orientation);
//				HAL_Delay(skip_turn_timer_buffer);
//				_turn_decide = 0;
//			}
//
//		}
//
//	}
//	if((sensor_calibrated_values[8] > black_detection_thresh_hold) && (sensor_calibrated_values[9] > black_detection_thresh_hold) &&
//			(sensor_calibrated_values[0] < white_detection_thresh_hold) && (sensor_calibrated_values[1] < white_detection_thresh_hold)){
//			if((*sensor_middle_on_line_number >= 3) && (*sensor_middle_on_line_number < 6)){
//
//				//line_gap_disable = 1;
//
//			PID_Forward_Rotation(base_speed, base_speed, orientation);
//			HAL_Delay(first_timer_buffer);
//			PID_Motor_All_Break();
//
//			HAL_Delay(1000);
//
//			agv_turn_count += 1;
//
//			HAL_GPIO_TogglePin(GPIOG, GPIO_PIN_7);
//
//			if(decision_array[agv_turn_count - 1] == 'R'){
//
//				PID_Motor_Turn_Right(base_speed, orientation);
//				HAL_Delay(second_timer_buffer);
//				PID_Motor_All_Break();
//
//				HAL_Delay(1000);
//
//				_turn_decide = 'R';
//			}
//			if(decision_array[agv_turn_count - 1] == 'F'){
//
//				PID_Forward_Rotation(base_speed, base_speed, orientation);
//				HAL_Delay(skip_turn_timer_buffer);
//				_turn_decide = 0;
//			}
//		}
//
//	}
//
//
//
//
//	if(_turn_decide == 'L'){
//		while((sensor_calibrated_values[5] < white_detection_thresh_hold) || (sensor_calibrated_values[6] < white_detection_thresh_hold)){
//			  Line_Sensor_Calculation(&front_array);
//			  Line_Sensor_Calculation(&back_array);
//
//			PID_Motor_Turn_Left(base_speed, orientation);
//		}
//		PID_Motor_All_Break();
//		_turn_decide = 0;
//
//
//		//line_gap_disable = 0;
//
////		else if((sensor_calibrated_values[7] > black_detection_thresh_hold) || (sensor_calibrated_values[8] > black_detection_thresh_hold)){
////
////
////		}
//
//	}
//	if(_turn_decide == 'R'){
//		while((sensor_calibrated_values[6] < white_detection_thresh_hold) || (sensor_calibrated_values[5] < white_detection_thresh_hold)){
//			  Line_Sensor_Calculation(&front_array);
//			  Line_Sensor_Calculation(&back_array);
//
//			PID_Motor_Turn_Right(base_speed, orientation);
//		}
//		PID_Motor_All_Break();
//		_turn_decide = 0;
//
//		//line_gap_disable = 0;
////		else if((sensor_calibrated_values[4] > black_detection_thresh_hold) || (sensor_calibrated_values[3] > black_detection_thresh_hold)){
////
////		}
//	}
//
//
//}

void AGV_Turn_Detection_Completion(volatile uint16_t *sensor_calibrated_values,
								   volatile uint8_t  *sensor_middle_on_line_number,
								   volatile uint8_t  *sensor_total_on_line_number,
								   	   	   	uint8_t  *decision_array,
											uint16_t *orientation){
#define white_detection_thresh_hold 500
#define black_detection_thresh_hold 500
#define sensor_mid_on_line_thresh_hold 1
#define first_timer_buffer 600
#define second_timer_buffer 300
#define skip_turn_timer_buffer 200
#define base_speed 50

	uint8_t _turn_decide = 0;

	if((*sensor_middle_on_line_number >= 3) && (*sensor_middle_on_line_number <= 6)){
		if(((sensor_calibrated_values[8] > black_detection_thresh_hold) && (sensor_calibrated_values[9] > black_detection_thresh_hold)) ||
			((sensor_calibrated_values[0] > black_detection_thresh_hold) && (sensor_calibrated_values[1] > black_detection_thresh_hold))){

			HAL_GPIO_WritePin(TURN_LED_GREEN_GPIO_Port, TURN_LED_GREEN_Pin, SET);
			HAL_GPIO_WritePin(TURN_LED_RED_GPIO_Port, TURN_LED_RED_Pin, RESET);

			PID_Forward_Rotation(base_speed, base_speed, orientation);
			HAL_Delay(first_timer_buffer);
			PID_Motor_All_Break();

			HAL_Delay(1000);

			agv_turn_count += 1;

			HAL_GPIO_TogglePin(GPIOG, GPIO_PIN_7);

			if(decision_array[agv_turn_count - 1] == 'L'){

				PID_Motor_Turn_Left(base_speed, orientation);
				HAL_Delay(second_timer_buffer);
				PID_Motor_All_Break();

				HAL_Delay(1000);

				_turn_decide = 'L';
			}
			else if(decision_array[agv_turn_count - 1] == 'R'){

				PID_Motor_Turn_Right(base_speed, orientation);
				HAL_Delay(second_timer_buffer);
				PID_Motor_All_Break();

				HAL_Delay(1000);

				_turn_decide = 'R';
			}

			else if(decision_array[agv_turn_count - 1] == 'F'){

				PID_Forward_Rotation(base_speed, base_speed, orientation);
				HAL_Delay(skip_turn_timer_buffer);
				_turn_decide = 0;
				HAL_GPIO_WritePin(TURN_LED_GREEN_GPIO_Port, TURN_LED_GREEN_Pin, RESET);
				HAL_GPIO_WritePin(TURN_LED_RED_GPIO_Port, TURN_LED_RED_Pin, SET);
			}
			if(decision_array[agv_turn_count - 1] == 'E'){

				PID_Motor_All_Break();

				Current_Station = Target_Station;

				On_Task = 0xF00F;

				if(agv_orientation == 0xF00F){
					agv_orientation = 0xF11F;
				}
				else if(agv_orientation == 0xF11F){
					agv_orientation = 0xF00F;
				}

				_turn_decide = 0;
				agv_turn_count = 0;
				HAL_GPIO_WritePin(TURN_LED_GREEN_GPIO_Port, TURN_LED_GREEN_Pin, RESET);
				HAL_GPIO_WritePin(TURN_LED_RED_GPIO_Port, TURN_LED_RED_Pin, SET);
			}

		}
	}

	Line_Sensor_Calculation(&front_array);
	Line_Sensor_Calculation(&back_array);

	if(_turn_decide == 'L'){
		while((sensor_calibrated_values[5] < white_detection_thresh_hold) || (sensor_calibrated_values[6] < white_detection_thresh_hold)){
			  Line_Sensor_Calculation(&front_array);
			  Line_Sensor_Calculation(&back_array);

			PID_Motor_Turn_Left(base_speed, orientation);
		}
		PID_Motor_All_Break();
		_turn_decide = 0;
		HAL_GPIO_WritePin(TURN_LED_GREEN_GPIO_Port, TURN_LED_GREEN_Pin, RESET);
		HAL_GPIO_WritePin(TURN_LED_RED_GPIO_Port, TURN_LED_RED_Pin, SET);
	}

	else if(_turn_decide == 'R'){
		while((sensor_calibrated_values[6] < white_detection_thresh_hold) || (sensor_calibrated_values[5] < white_detection_thresh_hold)){
			  Line_Sensor_Calculation(&front_array);
			  Line_Sensor_Calculation(&back_array);

			PID_Motor_Turn_Right(base_speed, orientation);
		}
		PID_Motor_All_Break();
		_turn_decide = 0;
		HAL_GPIO_WritePin(TURN_LED_GREEN_GPIO_Port, TURN_LED_GREEN_Pin, RESET);
		HAL_GPIO_WritePin(TURN_LED_RED_GPIO_Port, TURN_LED_RED_Pin, SET);
	}

}

//void Startup_RFID(){
//
//	PN532_SPI_Init(&pn532);
//	//HAL_GPIO_WritePin(RFID_SSF_GPIO_Port, RFID_SSF_Pin, 0);
//
//	if(PN532_GetFirmwareVersion(&pn532, uid_version) != PN532_STATUS_OK)
//	{
//		while(1){
//
//		}
//	}
//
//	PN532_SamConfiguration(&pn532);
//
//}
//void AGV_RFID_Detection(){
//	uid_len = PN532_ReadPassiveTarget(&pn532, uid, PN532_MIFARE_ISO14443A, 100);
//
//	if(uid_len >= 4){
//		Station_id[0] = uid[0];
//		Station_id[1] = uid[1];
//		Station_id[2] = uid[2];
//		Station_id[3] = uid[3];
//		Station_id[4] = uid[4];
//	}
//}

void HAL_GPIO_EXTI_Callback(uint16_t GPIO_Pin){
	if(GPIO_Pin == GPIO_PIN_0){
		Station = 1;
	}

	if(GPIO_Pin == GPIO_PIN_1){
		Station = 2;
	}

	if(GPIO_Pin == GPIO_PIN_2){
		Station = 3;
	}

	if(GPIO_Pin == GPIO_PIN_3){
		Station = 0;
	}

	if(GPIO_Pin == GPIO_PIN_4){
		HAL_GPIO_TogglePin(GPIOG, GPIO_PIN_7);
	}

	if(GPIO_Pin == myLoRa.DIO0_pin){
		LoRa_receive(&myLoRa, LoraRxBuffer, 128);
		HAL_GPIO_TogglePin(LORA_RX_LED_GPIO_Port, LORA_RX_LED_Pin);
		lora_receive_toggle = 255;

	}
}

void HAL_UARTEx_RxEventCallback(UART_HandleTypeDef *huart, uint16_t Size)
{
	//rs485_time2 = HAL_GetTick();
	//rs485_exc_time = rs485_time2 - rs485_time1;

//	rs485_fail_check = 0;
	if(huart->Instance == USART1){
		rs485_UART_receive_handler(&m1_driver);
	}
	if(huart->Instance == USART3){
		rs485_UART_receive_handler(&m2_driver);
	}
}

void HAL_TIM_PeriodElapsedCallback(TIM_HandleTypeDef* htim)
{
    if(htim->Instance == TIM3){
    	rs485_connection_lost_handler(&m1_driver);

    }
    if(htim->Instance == TIM4){
    	rs485_connection_lost_handler(&m2_driver);

    }
}

void debug_led(){
	if(agv_orientation == 0xF00F){
		HAL_GPIO_WritePin(ORIENTATION_LED_GREEN_GPIO_Port, ORIENTATION_LED_GREEN_Pin, SET);
		HAL_GPIO_WritePin(ORIENTATION_LED_RED_GPIO_Port, ORIENTATION_LED_RED_Pin, RESET);
	}
	else if(agv_orientation == 0xF11F){
		HAL_GPIO_WritePin(ORIENTATION_LED_GREEN_GPIO_Port, ORIENTATION_LED_GREEN_Pin, RESET);
		HAL_GPIO_WritePin(ORIENTATION_LED_RED_GPIO_Port, ORIENTATION_LED_RED_Pin, SET);
	}

	if(On_Task == 0xF11F){
		HAL_GPIO_WritePin(ONTASK_LED_GREEN_GPIO_Port, ONTASK_LED_GREEN_Pin, SET);
		HAL_GPIO_WritePin(ONTASK_LED_RED_GPIO_Port, ONTASK_LED_RED_Pin, RESET);
	}
	else if(On_Task == 0xF00F){
		HAL_GPIO_WritePin(ONTASK_LED_GREEN_GPIO_Port, ONTASK_LED_GREEN_Pin, RESET);
		HAL_GPIO_WritePin(ONTASK_LED_RED_GPIO_Port, ONTASK_LED_RED_Pin, SET);
	}
}

//void rs485m2_send_data(uint8_t *data){
//	if(rs485m2_isbusy == 0){
//		HAL_GPIO_WritePin(TX_ENM2_GPIO_Port, TX_ENM2_Pin, GPIO_PIN_SET);
//		HAL_UART_Transmit(&huart3, data, 8, 500);
//		HAL_GPIO_WritePin(TX_ENM2_GPIO_Port,TX_ENM2_Pin , GPIO_PIN_RESET);
//		rs485m2_isbusy = 255;
//		//rs485_time1 = HAL_GetTick();
//	}
//}

//void rs485_send_data(uint8_t *data)
//{
//
//	if(rs485_isbusy == 0){
//		HAL_GPIO_WritePin(TX_EN_GPIO_Port, TX_EN_Pin, GPIO_PIN_SET);
//		HAL_UART_Transmit(&huart1, data, 8, 500);
//		HAL_GPIO_WritePin(TX_EN_GPIO_Port,TX_EN_Pin , GPIO_PIN_RESET);
//		rs485_isbusy = 255;
//		//rs485_time1 = HAL_GetTick();
//	}
	//HAL_Delay(5);
//	else{
//		if(rs485_fail_check < 0xffff){
//			rs485_fail_check++;
//		}
//		else{
//			//Lost Connection to RS485
//			rs485_isbusy = 0;
//			HAL_Delay(20);
//		}
//
//		if(rs485_last_fail_check == 0xffff){
//			if(rs485_fail_check < 0xffff){
//				//Regained Connection to RS485
//
//				motor_enable_velocity_mode(0x01);
//				motor_enable_velocity_mode(0x02);
//				//rs485_connectivity++;
//			}
//		}
//		rs485_last_fail_check = rs485_fail_check;
//	}
//}

//void motor_enable_velocity_mode(uint8_t id){
//	  rs485_TxData[0] = id;
//	  rs485_TxData[1] = 0x06;  // Function code
//	  //address 2032 -> Operating Mode
//	  rs485_TxData[2] = 0x20;  // High 8 bit register address
//	  rs485_TxData[3] = 0x32;  // Low  8 bit register address
//	  //data 0x03 -> Set Velocity Mode
//	  rs485_TxData[4] = 0x00;  // High 8 bit register data
//	  rs485_TxData[5] = 0x03;  // Low  8 bit register data
//	  uint16_t crc = crc16(rs485_TxData, 6);
//	  rs485_TxData[6] = crc&0xFF;
//	  rs485_TxData[7] = (crc>>8)&0xFF;
//	  rs485_send_data(rs485_TxData);
//
//
//	  rs485_TxData[0] = id;
//	  rs485_TxData[1] = 0x06;  // Function code
//	  //address 2031 -> Control Word
//	  rs485_TxData[2] = 0x20;  // High 8 bit register address
//	  rs485_TxData[3] = 0x31;  // Low  8 bit register address
//	  //data 0x08 -> Enable Motor
//	  rs485_TxData[4] = 0x00;  // High 8 bit register data
//	  rs485_TxData[5] = 0x08;  // Low  8 bit register data
//	  crc = crc16(rs485_TxData, 6);
//	  rs485_TxData[6] = crc&0xFF;
//	  rs485_TxData[7] = (crc>>8)&0xFF;
//	  rs485_send_data(rs485_TxData);
//
//}

//void set_speed(uint8_t id, uint16_t speed, uint8_t dir){
//
//	rs485_TxData[0] = id;
//	rs485_TxData[1] = 0x06;  // Function code
//	//address 203A -> Target Speed
//	rs485_TxData[2] = 0x20;  // High 8 bit register address
//	rs485_TxData[3] = 0x3A;  // Low  8 bit register address
//	// Set Speed and Direction
//	if(dir == 0){
//		rs485_TxData[4] = (speed>>8)&0xFF; // High 8 bit register data
//		rs485_TxData[5] = speed&0xFF; // Low  8 bit register address
//	}
//	if(dir == 1){
//		speed = (~speed) + 1;
//		rs485_TxData[4] = (speed>>8)&0xFF; // High 8 bit register data
//		rs485_TxData[5] = speed&0xFF; // Low  8 bit register address
//	}
//	uint16_t crc = crc16(rs485_TxData, 6);
//	rs485_TxData[6] = crc&0xFF;
//	rs485_TxData[7] = (crc>>8)&0xFF;
//	rs485_send_data(rs485_TxData);
//}

/* USER CODE END 0 */

int main(void)
{

  /* MCU Configuration--------------------------------------------------------*/

  /* Reset of all peripherals, Initializes the Flash interface and the Systick. */
  HAL_Init();

  /* Configure the system clock */
  SystemClock_Config();

  /* Configure the peripherals common clocks */
  PeriphCommonClock_Config();

  /* Initialize all configured peripherals */
  MX_GPIO_Init();
  MX_DMA_Init();
  MX_ADC1_Init();
  MX_ADC3_Init();
  MX_USART1_UART_Init();
  MX_TIM2_Init();
  MX_SPI1_Init();
  MX_USART3_UART_Init();
  MX_TIM3_Init();
  MX_TIM4_Init();
  /* USER CODE BEGIN 2 */

  m1_driver.rs485_id = 0x01;
  m1_driver.rs485_huart = &huart1;
  m1_driver.rs485_timer = &htim3;
  m1_driver.rs485_enable_port = RS485_M1_TX_EN_GPIO_Port;
  m1_driver.rs485_enable_pin = RS485_M1_TX_EN_Pin;
  m1_driver.rs485_rx_led_port = RS485_M1_RX_LED_GPIO_Port;
  m1_driver.rs485_rx_led_pin = RS485_M1_RX_LED_Pin;

  m2_driver.rs485_id = 0x02;
  m2_driver.rs485_huart = &huart3;
  m2_driver.rs485_timer = &htim4;
  m2_driver.rs485_enable_port = RS485_M2_TX_EN_GPIO_Port;
  m2_driver.rs485_enable_pin = RS485_M2_TX_EN_Pin;
  m2_driver.rs485_rx_led_port = RS485_M2_RX_LED_GPIO_Port;
  m2_driver.rs485_rx_led_pin = RS485_M2_RX_LED_Pin;

  rs485_init(&m1_driver);
  rs485_init(&m2_driver);

  rs485_enable_velocity_mode(&m1_driver);
  rs485_enable_velocity_mode(&m2_driver);

  //HAL_TIM_PWM_Start(&htim2, TIM_CHANNEL_1);
  //HAL_TIM_PWM_Start(&htim2, TIM_CHANNEL_2);

  myLoRa = newLoRa();

  myLoRa.CS_port         = LORA_NSS_GPIO_Port;
  myLoRa.CS_pin          = LORA_NSS_Pin;
  myLoRa.reset_port      = LORA_RST_GPIO_Port;
  myLoRa.reset_pin       = LORA_RST_Pin;
  myLoRa.DIO0_port       = LORA_DIO0_GPIO_Port;
  myLoRa.DIO0_pin        = LORA_DIO0_Pin;
  myLoRa.hSPIx           = &hspi1;

  myLoRa.frequency             = 433;             // default = 433 MHz
  myLoRa.spredingFactor        = SF_7;            // default = SF_7
  myLoRa.bandWidth             = BW_125KHz;       // default = BW_125KHz
  myLoRa.crcRate               = CR_4_5;          // default = CR_4_5
  myLoRa.power                 = POWER_20db;      // default = 20db
  myLoRa.overCurrentProtection = 100;             // default = 100 mA
  myLoRa.preamble              = 8;              // default = 8;

  if(LoRa_init(&myLoRa) == LORA_OK){
	  LoRa_stat = 1;
  }

  LoRa_startReceiving(&myLoRa);

  LoraTxBuffer[0] = 0xAA;
  LoraTxBuffer[1] = 0xBB;
  LoraTxBuffer[2] = 0xCC;

  //LoRa_transmit(&myLoRa, LoraTxBuffer, 3, 500);
  HAL_ADC_Start_DMA(&hadc1, (uint32_t*) front_array.ir_sen_val_dma, line_sensor_front_channel_number);
  ir_array_init(&front_array,
                line_sensor_front_values_calibrated,
                line_sensor_front_max_sensor_vales,
                line_sensor_front_min_sensor_vales,
                &line_sensor_front_channel_number,
                &line_sensor_front_read_line_value,
                &line_sensor_front_read_line_old_value,
                &line_sensor_front_on_line_total_number,
                &line_sensor_front_on_line_middle_number,
                &line_sensor_front_on_line_left_number,
                &line_sensor_front_on_line_right_number,
                &line_sensor_front_threshold);

  HAL_ADC_Start_DMA(&hadc3, (uint32_t*) back_array.ir_sen_val_dma, line_sensor_back_channel_number);
  ir_array_init(&back_array,
                line_sensor_back_values_calibrated,
                line_sensor_back_max_sensor_vales,
                line_sensor_back_min_sensor_vales,
                &line_sensor_back_channel_number,
                &line_sensor_back_read_line_value,
                &line_sensor_back_read_line_old_value,
                &line_sensor_back_on_line_total_number,
                &line_sensor_back_on_line_middle_number,
                &line_sensor_back_on_line_left_number,
                &line_sensor_back_on_line_right_number,
                &line_sensor_back_threshold);

  Line_Sensor_Calculation(&front_array);
  Line_Sensor_Calculation(&back_array);

  if((back_array.ir_sen_on_line_total_num >= 9) &&(front_array.ir_sen_on_line_total_num >= 1)){
	  agv_orientation = 0xF00F;
  }
  if((front_array.ir_sen_on_line_total_num >= 9) && (back_array.ir_sen_on_line_total_num >= 1)){
	  agv_orientation = 0xF11F;
  }

  HAL_GPIO_WritePin(TURN_LED_GREEN_GPIO_Port, TURN_LED_GREEN_Pin, RESET);
  HAL_GPIO_WritePin(TURN_LED_RED_GPIO_Port, TURN_LED_RED_Pin, SET);

  /* USER CODE END 2 */

  /* Infinite loop */
  /* USER CODE BEGIN WHILE */

  while (1)
  {
	  debug_led();
	  //agv_orientation = 0xF00F;
////
//	  if(lora_receive_toggle == 255){
//		  if(LoRa_transmit(&myLoRa, LoraTxBuffer, 26, 500) == 1){
//
//			  HAL_GPIO_TogglePin(LORA_TX_LED_GPIO_Port, LORA_TX_LED_Pin);
//		  }
//		  lora_receive_toggle = 0;
//	  }
//
	  Line_Sensor_Calculation(&front_array);
	  Line_Sensor_Calculation(&back_array);
////
//	  PID_control(&front_array.ir_sen_read_line_val, &agv_orientation);
////	  //PID_control(&back_array.ir_sen_read_line_val, &agv_orientation);
////
//	  PID_Forward_Rotation(pid_motor_speed_A, pid_motor_speed_B, &agv_orientation);

	  //PID_Forward_Rotation(10, 100, &agv_orientation);
//	  HAL_Delay(2000);
	  //PID_Motor_Turn_Left(100, &agv_orientation);
//	  HAL_Delay(2000);
	  //PID_Motor_Turn_Right(20, &agv_orientation);
	  //HAL_Delay(2000);
	  //PID_Motor_All_Break();
	  //HAL_Delay(2000);

	  	  if(On_Task == 0xF11F){
	 		  if(agv_orientation == 0xF00F){

	 			  Line_Sensor_Calculation(&front_array);

				  AGV_Turn_Detection_Completion(front_array.ir_sen_val_cal,
											   &front_array.ir_sen_on_line_mid_num,
											   &front_array.ir_sen_on_line_total_num,
												on_task_decisions,
											   &agv_orientation);

				  PID_control(&front_array.ir_sen_read_line_val, &agv_orientation);

				  PID_Forward_Rotation(pid_motor_speed_A, pid_motor_speed_B, &agv_orientation);

	  		  }
	  		  if(agv_orientation == 0xF11F){

	  			  Line_Sensor_Calculation(&back_array);

				  AGV_Turn_Detection_Completion(back_array.ir_sen_val_cal,
											   &back_array.ir_sen_on_line_mid_num,
											   &back_array.ir_sen_on_line_total_num,
												on_task_decisions,
											   &agv_orientation);

				  PID_control(&back_array.ir_sen_read_line_val, &agv_orientation);

				  PID_Forward_Rotation(pid_motor_speed_A, pid_motor_speed_B, &agv_orientation);

	  		  }

	  	  }
	  	  if(On_Task == 0xF00F){
	  		  AGV_waiting();
	  		  PID_Motor_All_Break();
	  	  }

    /* USER CODE END WHILE */

  }
}

void SystemClock_Config(void)
{
  RCC_OscInitTypeDef RCC_OscInitStruct = {0};
  RCC_ClkInitTypeDef RCC_ClkInitStruct = {0};

  /** Supply configuration update enable
  */
  HAL_PWREx_ConfigSupply(PWR_LDO_SUPPLY);

  /** Configure the main internal regulator output voltage
  */
  __HAL_PWR_VOLTAGESCALING_CONFIG(PWR_REGULATOR_VOLTAGE_SCALE0);

  while(!__HAL_PWR_GET_FLAG(PWR_FLAG_VOSRDY)) {}

  /** Initializes the RCC Oscillators according to the specified parameters
  * in the RCC_OscInitTypeDef structure.
  */
  RCC_OscInitStruct.OscillatorType = RCC_OSCILLATORTYPE_HSI|RCC_OSCILLATORTYPE_HSE;
  RCC_OscInitStruct.HSEState = RCC_HSE_ON;
  RCC_OscInitStruct.HSIState = RCC_HSI_DIV1;
  RCC_OscInitStruct.HSICalibrationValue = 64;
  RCC_OscInitStruct.PLL.PLLState = RCC_PLL_ON;
  RCC_OscInitStruct.PLL.PLLSource = RCC_PLLSOURCE_HSE;
  RCC_OscInitStruct.PLL.PLLM = 2;
  RCC_OscInitStruct.PLL.PLLN = 44;
  RCC_OscInitStruct.PLL.PLLP = 1;
  RCC_OscInitStruct.PLL.PLLQ = 3;
  RCC_OscInitStruct.PLL.PLLR = 2;
  RCC_OscInitStruct.PLL.PLLRGE = RCC_PLL1VCIRANGE_3;
  RCC_OscInitStruct.PLL.PLLVCOSEL = RCC_PLL1VCOWIDE;
  RCC_OscInitStruct.PLL.PLLFRACN = 0;
  if (HAL_RCC_OscConfig(&RCC_OscInitStruct) != HAL_OK)
  {
    Error_Handler();
  }

  /** Initializes the CPU, AHB and APB buses clocks
  */
  RCC_ClkInitStruct.ClockType = RCC_CLOCKTYPE_HCLK|RCC_CLOCKTYPE_SYSCLK
                              |RCC_CLOCKTYPE_PCLK1|RCC_CLOCKTYPE_PCLK2
                              |RCC_CLOCKTYPE_D3PCLK1|RCC_CLOCKTYPE_D1PCLK1;
  RCC_ClkInitStruct.SYSCLKSource = RCC_SYSCLKSOURCE_PLLCLK;
  RCC_ClkInitStruct.SYSCLKDivider = RCC_SYSCLK_DIV1;
  RCC_ClkInitStruct.AHBCLKDivider = RCC_HCLK_DIV2;
  RCC_ClkInitStruct.APB3CLKDivider = RCC_APB3_DIV2;
  RCC_ClkInitStruct.APB1CLKDivider = RCC_APB1_DIV2;
  RCC_ClkInitStruct.APB2CLKDivider = RCC_APB2_DIV2;
  RCC_ClkInitStruct.APB4CLKDivider = RCC_APB4_DIV2;

  if (HAL_RCC_ClockConfig(&RCC_ClkInitStruct, FLASH_LATENCY_3) != HAL_OK)
  {
    Error_Handler();
  }
}

void PeriphCommonClock_Config(void)
{
  RCC_PeriphCLKInitTypeDef PeriphClkInitStruct = {0};

  /** Initializes the peripherals clock
  */
  PeriphClkInitStruct.PeriphClockSelection = RCC_PERIPHCLK_ADC|RCC_PERIPHCLK_CKPER;
  PeriphClkInitStruct.PLL2.PLL2M = 2;
  PeriphClkInitStruct.PLL2.PLL2N = 15;
  PeriphClkInitStruct.PLL2.PLL2P = 2;
  PeriphClkInitStruct.PLL2.PLL2Q = 2;
  PeriphClkInitStruct.PLL2.PLL2R = 2;
  PeriphClkInitStruct.PLL2.PLL2RGE = RCC_PLL2VCIRANGE_3;
  PeriphClkInitStruct.PLL2.PLL2VCOSEL = RCC_PLL2VCOWIDE;
  PeriphClkInitStruct.PLL2.PLL2FRACN = 2950;
  PeriphClkInitStruct.CkperClockSelection = RCC_CLKPSOURCE_HSI;
  PeriphClkInitStruct.AdcClockSelection = RCC_ADCCLKSOURCE_PLL2;
  if (HAL_RCCEx_PeriphCLKConfig(&PeriphClkInitStruct) != HAL_OK)
  {
    Error_Handler();
  }
}

static void MX_ADC1_Init(void)
{

  ADC_MultiModeTypeDef multimode = {0};
  ADC_ChannelConfTypeDef sConfig = {0};

  /** Common config
  */
  hadc1.Instance = ADC1;
  hadc1.Init.ClockPrescaler = ADC_CLOCK_ASYNC_DIV1;
  hadc1.Init.Resolution = ADC_RESOLUTION_12B;
  hadc1.Init.ScanConvMode = ADC_SCAN_ENABLE;
  hadc1.Init.EOCSelection = ADC_EOC_SINGLE_CONV;
  hadc1.Init.LowPowerAutoWait = DISABLE;
  hadc1.Init.ContinuousConvMode = ENABLE;
  hadc1.Init.NbrOfConversion = 10;
  hadc1.Init.DiscontinuousConvMode = DISABLE;
  hadc1.Init.ExternalTrigConv = ADC_SOFTWARE_START;
  hadc1.Init.ExternalTrigConvEdge = ADC_EXTERNALTRIGCONVEDGE_NONE;
  hadc1.Init.ConversionDataManagement = ADC_CONVERSIONDATA_DMA_CIRCULAR;
  hadc1.Init.Overrun = ADC_OVR_DATA_OVERWRITTEN;
  hadc1.Init.LeftBitShift = ADC_LEFTBITSHIFT_NONE;
  hadc1.Init.OversamplingMode = DISABLE;
  hadc1.Init.Oversampling.Ratio = 1;
  if (HAL_ADC_Init(&hadc1) != HAL_OK)
  {
    Error_Handler();
  }

  /** Configure the ADC multi-mode
  */
  multimode.Mode = ADC_MODE_INDEPENDENT;
  if (HAL_ADCEx_MultiModeConfigChannel(&hadc1, &multimode) != HAL_OK)
  {
    Error_Handler();
  }

  /** Configure Regular Channel
  */
  sConfig.Channel = ADC_CHANNEL_11;
  sConfig.Rank = ADC_REGULAR_RANK_1;
  sConfig.SamplingTime = ADC_SAMPLETIME_64CYCLES_5;
  sConfig.SingleDiff = ADC_SINGLE_ENDED;
  sConfig.OffsetNumber = ADC_OFFSET_NONE;
  sConfig.Offset = 0;
  sConfig.OffsetSignedSaturation = DISABLE;
  if (HAL_ADC_ConfigChannel(&hadc1, &sConfig) != HAL_OK)
  {
    Error_Handler();
  }

  /** Configure Regular Channel
  */
  sConfig.Channel = ADC_CHANNEL_10;
  sConfig.Rank = ADC_REGULAR_RANK_2;
  if (HAL_ADC_ConfigChannel(&hadc1, &sConfig) != HAL_OK)
  {
    Error_Handler();
  }

  /** Configure Regular Channel
  */
  sConfig.Channel = ADC_CHANNEL_9;
  sConfig.Rank = ADC_REGULAR_RANK_3;
  if (HAL_ADC_ConfigChannel(&hadc1, &sConfig) != HAL_OK)
  {
    Error_Handler();
  }

  /** Configure Regular Channel
  */
  sConfig.Channel = ADC_CHANNEL_8;
  sConfig.Rank = ADC_REGULAR_RANK_4;
  if (HAL_ADC_ConfigChannel(&hadc1, &sConfig) != HAL_OK)
  {
    Error_Handler();
  }

  /** Configure Regular Channel
  */
  sConfig.Channel = ADC_CHANNEL_7;
  sConfig.Rank = ADC_REGULAR_RANK_5;
  if (HAL_ADC_ConfigChannel(&hadc1, &sConfig) != HAL_OK)
  {
    Error_Handler();
  }

  /** Configure Regular Channel
  */
  sConfig.Channel = ADC_CHANNEL_6;
  sConfig.Rank = ADC_REGULAR_RANK_6;
  if (HAL_ADC_ConfigChannel(&hadc1, &sConfig) != HAL_OK)
  {
    Error_Handler();
  }

  /** Configure Regular Channel
  */
  sConfig.Channel = ADC_CHANNEL_5;
  sConfig.Rank = ADC_REGULAR_RANK_7;
  if (HAL_ADC_ConfigChannel(&hadc1, &sConfig) != HAL_OK)
  {
    Error_Handler();
  }

  /** Configure Regular Channel
  */
  sConfig.Channel = ADC_CHANNEL_4;
  sConfig.Rank = ADC_REGULAR_RANK_8;
  if (HAL_ADC_ConfigChannel(&hadc1, &sConfig) != HAL_OK)
  {
    Error_Handler();
  }

  /** Configure Regular Channel
  */
  sConfig.Channel = ADC_CHANNEL_3;
  sConfig.Rank = ADC_REGULAR_RANK_9;
  if (HAL_ADC_ConfigChannel(&hadc1, &sConfig) != HAL_OK)
  {
    Error_Handler();
  }

  /** Configure Regular Channel
  */
  sConfig.Channel = ADC_CHANNEL_2;
  sConfig.Rank = ADC_REGULAR_RANK_10;
  if (HAL_ADC_ConfigChannel(&hadc1, &sConfig) != HAL_OK)
  {
    Error_Handler();
  }

}

static void MX_ADC3_Init(void)
{

  ADC_ChannelConfTypeDef sConfig = {0};

  /** Common config
  */
  hadc3.Instance = ADC3;
  hadc3.Init.ClockPrescaler = ADC_CLOCK_ASYNC_DIV1;
  hadc3.Init.Resolution = ADC_RESOLUTION_12B;
  hadc3.Init.DataAlign = ADC3_DATAALIGN_RIGHT;
  hadc3.Init.ScanConvMode = ADC_SCAN_ENABLE;
  hadc3.Init.EOCSelection = ADC_EOC_SINGLE_CONV;
  hadc3.Init.LowPowerAutoWait = DISABLE;
  hadc3.Init.ContinuousConvMode = ENABLE;
  hadc3.Init.NbrOfConversion = 10;
  hadc3.Init.DiscontinuousConvMode = DISABLE;
  hadc3.Init.ExternalTrigConv = ADC_SOFTWARE_START;
  hadc3.Init.ExternalTrigConvEdge = ADC_EXTERNALTRIGCONVEDGE_NONE;
  hadc3.Init.DMAContinuousRequests = ENABLE;
  hadc3.Init.SamplingMode = ADC_SAMPLING_MODE_NORMAL;
  hadc3.Init.ConversionDataManagement = ADC_CONVERSIONDATA_DMA_CIRCULAR;
  hadc3.Init.Overrun = ADC_OVR_DATA_OVERWRITTEN;
  hadc3.Init.LeftBitShift = ADC_LEFTBITSHIFT_NONE;
  hadc3.Init.OversamplingMode = DISABLE;
  hadc3.Init.Oversampling.Ratio = ADC3_OVERSAMPLING_RATIO_2;
  if (HAL_ADC_Init(&hadc3) != HAL_OK)
  {
    Error_Handler();
  }

  /** Configure Regular Channel
  */
  sConfig.Channel = ADC_CHANNEL_9;
  sConfig.Rank = ADC_REGULAR_RANK_1;
  sConfig.SamplingTime = ADC3_SAMPLETIME_92CYCLES_5;
  sConfig.SingleDiff = ADC_SINGLE_ENDED;
  sConfig.OffsetNumber = ADC_OFFSET_NONE;
  sConfig.Offset = 0;
  sConfig.OffsetSign = ADC3_OFFSET_SIGN_NEGATIVE;
  if (HAL_ADC_ConfigChannel(&hadc3, &sConfig) != HAL_OK)
  {
    Error_Handler();
  }

  /** Configure Regular Channel
  */
  sConfig.Channel = ADC_CHANNEL_8;
  sConfig.Rank = ADC_REGULAR_RANK_2;
  if (HAL_ADC_ConfigChannel(&hadc3, &sConfig) != HAL_OK)
  {
    Error_Handler();
  }

  /** Configure Regular Channel
  */
  sConfig.Channel = ADC_CHANNEL_7;
  sConfig.Rank = ADC_REGULAR_RANK_3;
  if (HAL_ADC_ConfigChannel(&hadc3, &sConfig) != HAL_OK)
  {
    Error_Handler();
  }

  /** Configure Regular Channel
  */
  sConfig.Channel = ADC_CHANNEL_6;
  sConfig.Rank = ADC_REGULAR_RANK_4;
  if (HAL_ADC_ConfigChannel(&hadc3, &sConfig) != HAL_OK)
  {
    Error_Handler();
  }

  /** Configure Regular Channel
  */
  sConfig.Channel = ADC_CHANNEL_5;
  sConfig.Rank = ADC_REGULAR_RANK_5;
  if (HAL_ADC_ConfigChannel(&hadc3, &sConfig) != HAL_OK)
  {
    Error_Handler();
  }

  /** Configure Regular Channel
  */
  sConfig.Channel = ADC_CHANNEL_4;
  sConfig.Rank = ADC_REGULAR_RANK_6;
  if (HAL_ADC_ConfigChannel(&hadc3, &sConfig) != HAL_OK)
  {
    Error_Handler();
  }

  /** Configure Regular Channel
  */
  sConfig.Channel = ADC_CHANNEL_3;
  sConfig.Rank = ADC_REGULAR_RANK_7;
  if (HAL_ADC_ConfigChannel(&hadc3, &sConfig) != HAL_OK)
  {
    Error_Handler();
  }

  /** Configure Regular Channel
  */
  sConfig.Channel = ADC_CHANNEL_2;
  sConfig.Rank = ADC_REGULAR_RANK_8;
  if (HAL_ADC_ConfigChannel(&hadc3, &sConfig) != HAL_OK)
  {
    Error_Handler();
  }

  /** Configure Regular Channel
  */
  sConfig.Channel = ADC_CHANNEL_1;
  sConfig.Rank = ADC_REGULAR_RANK_9;
  if (HAL_ADC_ConfigChannel(&hadc3, &sConfig) != HAL_OK)
  {
    Error_Handler();
  }

  /** Configure Regular Channel
  */
  sConfig.Channel = ADC_CHANNEL_0;
  sConfig.Rank = ADC_REGULAR_RANK_10;
  if (HAL_ADC_ConfigChannel(&hadc3, &sConfig) != HAL_OK)
  {
    Error_Handler();
  }

}

static void MX_SPI1_Init(void)
{

  /* SPI1 parameter configuration*/
  hspi1.Instance = SPI1;
  hspi1.Init.Mode = SPI_MODE_MASTER;
  hspi1.Init.Direction = SPI_DIRECTION_2LINES;
  hspi1.Init.DataSize = SPI_DATASIZE_8BIT;
  hspi1.Init.CLKPolarity = SPI_POLARITY_LOW;
  hspi1.Init.CLKPhase = SPI_PHASE_1EDGE;
  hspi1.Init.NSS = SPI_NSS_SOFT;
  hspi1.Init.BaudRatePrescaler = SPI_BAUDRATEPRESCALER_16;
  hspi1.Init.FirstBit = SPI_FIRSTBIT_MSB;
  hspi1.Init.TIMode = SPI_TIMODE_DISABLE;
  hspi1.Init.CRCCalculation = SPI_CRCCALCULATION_DISABLE;
  hspi1.Init.CRCPolynomial = 0x0;
  hspi1.Init.NSSPMode = SPI_NSS_PULSE_ENABLE;
  hspi1.Init.NSSPolarity = SPI_NSS_POLARITY_LOW;
  hspi1.Init.FifoThreshold = SPI_FIFO_THRESHOLD_01DATA;
  hspi1.Init.TxCRCInitializationPattern = SPI_CRC_INITIALIZATION_ALL_ZERO_PATTERN;
  hspi1.Init.RxCRCInitializationPattern = SPI_CRC_INITIALIZATION_ALL_ZERO_PATTERN;
  hspi1.Init.MasterSSIdleness = SPI_MASTER_SS_IDLENESS_00CYCLE;
  hspi1.Init.MasterInterDataIdleness = SPI_MASTER_INTERDATA_IDLENESS_00CYCLE;
  hspi1.Init.MasterReceiverAutoSusp = SPI_MASTER_RX_AUTOSUSP_DISABLE;
  hspi1.Init.MasterKeepIOState = SPI_MASTER_KEEP_IO_STATE_DISABLE;
  hspi1.Init.IOSwap = SPI_IO_SWAP_DISABLE;
  if (HAL_SPI_Init(&hspi1) != HAL_OK)
  {
    Error_Handler();
  }

}

static void MX_TIM2_Init(void)
{

  TIM_MasterConfigTypeDef sMasterConfig = {0};
  TIM_OC_InitTypeDef sConfigOC = {0};

  htim2.Instance = TIM2;
  htim2.Init.Prescaler = 1360;
  htim2.Init.CounterMode = TIM_COUNTERMODE_UP;
  htim2.Init.Period = 100;
  htim2.Init.ClockDivision = TIM_CLOCKDIVISION_DIV1;
  htim2.Init.AutoReloadPreload = TIM_AUTORELOAD_PRELOAD_ENABLE;
  if (HAL_TIM_PWM_Init(&htim2) != HAL_OK)
  {
    Error_Handler();
  }
  sMasterConfig.MasterOutputTrigger = TIM_TRGO_RESET;
  sMasterConfig.MasterSlaveMode = TIM_MASTERSLAVEMODE_DISABLE;
  if (HAL_TIMEx_MasterConfigSynchronization(&htim2, &sMasterConfig) != HAL_OK)
  {
    Error_Handler();
  }
  sConfigOC.OCMode = TIM_OCMODE_PWM1;
  sConfigOC.Pulse = 0;
  sConfigOC.OCPolarity = TIM_OCPOLARITY_HIGH;
  sConfigOC.OCFastMode = TIM_OCFAST_DISABLE;
  if (HAL_TIM_PWM_ConfigChannel(&htim2, &sConfigOC, TIM_CHANNEL_1) != HAL_OK)
  {
    Error_Handler();
  }
  __HAL_TIM_DISABLE_OCxPRELOAD(&htim2, TIM_CHANNEL_1);
  if (HAL_TIM_PWM_ConfigChannel(&htim2, &sConfigOC, TIM_CHANNEL_2) != HAL_OK)
  {
    Error_Handler();
  }
  __HAL_TIM_DISABLE_OCxPRELOAD(&htim2, TIM_CHANNEL_2);
  HAL_TIM_MspPostInit(&htim2);

}

static void MX_TIM3_Init(void)
{

  TIM_ClockConfigTypeDef sClockSourceConfig = {0};
  TIM_MasterConfigTypeDef sMasterConfig = {0};

  htim3.Instance = TIM3;
  htim3.Init.Prescaler = 500-1;
  htim3.Init.CounterMode = TIM_COUNTERMODE_UP;
  htim3.Init.Period = 55000-1;
  htim3.Init.ClockDivision = TIM_CLOCKDIVISION_DIV1;
  htim3.Init.AutoReloadPreload = TIM_AUTORELOAD_PRELOAD_ENABLE;
  if (HAL_TIM_Base_Init(&htim3) != HAL_OK)
  {
    Error_Handler();
  }
  sClockSourceConfig.ClockSource = TIM_CLOCKSOURCE_INTERNAL;
  if (HAL_TIM_ConfigClockSource(&htim3, &sClockSourceConfig) != HAL_OK)
  {
    Error_Handler();
  }
  sMasterConfig.MasterOutputTrigger = TIM_TRGO_RESET;
  sMasterConfig.MasterSlaveMode = TIM_MASTERSLAVEMODE_DISABLE;
  if (HAL_TIMEx_MasterConfigSynchronization(&htim3, &sMasterConfig) != HAL_OK)
  {
    Error_Handler();
  }

}

static void MX_TIM4_Init(void)
{

  TIM_ClockConfigTypeDef sClockSourceConfig = {0};
  TIM_MasterConfigTypeDef sMasterConfig = {0};

  htim4.Instance = TIM4;
  htim4.Init.Prescaler = 500-1;
  htim4.Init.CounterMode = TIM_COUNTERMODE_UP;
  htim4.Init.Period = 55000-1;
  htim4.Init.ClockDivision = TIM_CLOCKDIVISION_DIV1;
  htim4.Init.AutoReloadPreload = TIM_AUTORELOAD_PRELOAD_ENABLE;
  if (HAL_TIM_Base_Init(&htim4) != HAL_OK)
  {
    Error_Handler();
  }
  sClockSourceConfig.ClockSource = TIM_CLOCKSOURCE_INTERNAL;
  if (HAL_TIM_ConfigClockSource(&htim4, &sClockSourceConfig) != HAL_OK)
  {
    Error_Handler();
  }
  sMasterConfig.MasterOutputTrigger = TIM_TRGO_RESET;
  sMasterConfig.MasterSlaveMode = TIM_MASTERSLAVEMODE_DISABLE;
  if (HAL_TIMEx_MasterConfigSynchronization(&htim4, &sMasterConfig) != HAL_OK)
  {
    Error_Handler();
  }

}

static void MX_USART1_UART_Init(void)
{

  huart1.Instance = USART1;
  huart1.Init.BaudRate = 115200;
  huart1.Init.WordLength = UART_WORDLENGTH_8B;
  huart1.Init.StopBits = UART_STOPBITS_1;
  huart1.Init.Parity = UART_PARITY_NONE;
  huart1.Init.Mode = UART_MODE_TX_RX;
  huart1.Init.HwFlowCtl = UART_HWCONTROL_NONE;
  huart1.Init.OverSampling = UART_OVERSAMPLING_16;
  huart1.Init.OneBitSampling = UART_ONE_BIT_SAMPLE_DISABLE;
  huart1.Init.ClockPrescaler = UART_PRESCALER_DIV1;
  huart1.AdvancedInit.AdvFeatureInit = UART_ADVFEATURE_NO_INIT;
  if (HAL_UART_Init(&huart1) != HAL_OK)
  {
    Error_Handler();
  }
  if (HAL_UARTEx_SetTxFifoThreshold(&huart1, UART_TXFIFO_THRESHOLD_1_8) != HAL_OK)
  {
    Error_Handler();
  }
  if (HAL_UARTEx_SetRxFifoThreshold(&huart1, UART_RXFIFO_THRESHOLD_1_8) != HAL_OK)
  {
    Error_Handler();
  }
  if (HAL_UARTEx_DisableFifoMode(&huart1) != HAL_OK)
  {
    Error_Handler();
  }

}

static void MX_USART3_UART_Init(void)
{

  huart3.Instance = USART3;
  huart3.Init.BaudRate = 115200;
  huart3.Init.WordLength = UART_WORDLENGTH_8B;
  huart3.Init.StopBits = UART_STOPBITS_1;
  huart3.Init.Parity = UART_PARITY_NONE;
  huart3.Init.Mode = UART_MODE_TX_RX;
  huart3.Init.HwFlowCtl = UART_HWCONTROL_NONE;
  huart3.Init.OverSampling = UART_OVERSAMPLING_16;
  huart3.Init.OneBitSampling = UART_ONE_BIT_SAMPLE_DISABLE;
  huart3.Init.ClockPrescaler = UART_PRESCALER_DIV1;
  huart3.AdvancedInit.AdvFeatureInit = UART_ADVFEATURE_NO_INIT;
  if (HAL_UART_Init(&huart3) != HAL_OK)
  {
    Error_Handler();
  }
  if (HAL_UARTEx_SetTxFifoThreshold(&huart3, UART_TXFIFO_THRESHOLD_1_8) != HAL_OK)
  {
    Error_Handler();
  }
  if (HAL_UARTEx_SetRxFifoThreshold(&huart3, UART_RXFIFO_THRESHOLD_1_8) != HAL_OK)
  {
    Error_Handler();
  }
  if (HAL_UARTEx_DisableFifoMode(&huart3) != HAL_OK)
  {
    Error_Handler();
  }

}

static void MX_DMA_Init(void)
{

  /* DMA controller clock enable */
  __HAL_RCC_DMA1_CLK_ENABLE();

  /* DMA interrupt init */
  /* DMA1_Stream0_IRQn interrupt configuration */
  HAL_NVIC_SetPriority(DMA1_Stream0_IRQn, 0, 0);
  HAL_NVIC_EnableIRQ(DMA1_Stream0_IRQn);
  /* DMA1_Stream1_IRQn interrupt configuration */
  HAL_NVIC_SetPriority(DMA1_Stream1_IRQn, 0, 0);
  HAL_NVIC_EnableIRQ(DMA1_Stream1_IRQn);

}

static void MX_GPIO_Init(void)
{
  GPIO_InitTypeDef GPIO_InitStruct = {0};

  /* GPIO Ports Clock Enable */
  __HAL_RCC_GPIOE_CLK_ENABLE();
  __HAL_RCC_GPIOC_CLK_ENABLE();
  __HAL_RCC_GPIOF_CLK_ENABLE();
  __HAL_RCC_GPIOH_CLK_ENABLE();
  __HAL_RCC_GPIOA_CLK_ENABLE();
  __HAL_RCC_GPIOB_CLK_ENABLE();
  __HAL_RCC_GPIOD_CLK_ENABLE();
  __HAL_RCC_GPIOG_CLK_ENABLE();

  /*Configure GPIO pin Output Level */
  HAL_GPIO_WritePin(GPIOC, GPIO_PIN_13, GPIO_PIN_RESET);

  /*Configure GPIO pin Output Level */
  HAL_GPIO_WritePin(GPIOA, IN3_Pin|IN4_Pin|IN2_Pin|IN1_Pin, GPIO_PIN_RESET);

  /*Configure GPIO pin Output Level */
  HAL_GPIO_WritePin(GPIOE, TRIG_Pin|RS485_M2_TX_EN_Pin, GPIO_PIN_RESET);

  /*Configure GPIO pin Output Level */
  HAL_GPIO_WritePin(GPIOB, RS485_M2_RX_LED_Pin|RS485_M1_TX_EN_Pin, GPIO_PIN_RESET);

  /*Configure GPIO pin Output Level */
  HAL_GPIO_WritePin(GPIOD, RS485_M1_RX_LED_Pin|TURN_LED_RED_Pin|TURN_LED_GREEN_Pin|ORIENTATION_LED_RED_Pin
                          |ORIENTATION_LED_GREEN_Pin|ONTASK_LED_RED_Pin|ONTASK_LED_GREEN_Pin, GPIO_PIN_RESET);

  /*Configure GPIO pin Output Level */
  HAL_GPIO_WritePin(GPIOG, GPIO_PIN_7|LORA_TX_LED_Pin, GPIO_PIN_RESET);

  /*Configure GPIO pin Output Level */
  HAL_GPIO_WritePin(LORA_RX_LED_GPIO_Port, LORA_RX_LED_Pin, GPIO_PIN_SET);

  /*Configure GPIO pin Output Level */
  HAL_GPIO_WritePin(GPIOG, LORA_NSS_Pin|LORA_RST_Pin, GPIO_PIN_SET);

  /*Configure GPIO pins : PE2 PE3 PE4 PE0
                           PE1 */
  GPIO_InitStruct.Pin = GPIO_PIN_2|GPIO_PIN_3|GPIO_PIN_4|GPIO_PIN_0
                          |GPIO_PIN_1;
  GPIO_InitStruct.Mode = GPIO_MODE_IT_FALLING;
  GPIO_InitStruct.Pull = GPIO_NOPULL;
  HAL_GPIO_Init(GPIOE, &GPIO_InitStruct);

  /*Configure GPIO pin : PC13 */
  GPIO_InitStruct.Pin = GPIO_PIN_13;
  GPIO_InitStruct.Mode = GPIO_MODE_OUTPUT_PP;
  GPIO_InitStruct.Pull = GPIO_NOPULL;
  GPIO_InitStruct.Speed = GPIO_SPEED_FREQ_LOW;
  HAL_GPIO_Init(GPIOC, &GPIO_InitStruct);

  /*Configure GPIO pins : IN3_Pin IN4_Pin IN2_Pin IN1_Pin */
  GPIO_InitStruct.Pin = IN3_Pin|IN4_Pin|IN2_Pin|IN1_Pin;
  GPIO_InitStruct.Mode = GPIO_MODE_OUTPUT_PP;
  GPIO_InitStruct.Pull = GPIO_NOPULL;
  GPIO_InitStruct.Speed = GPIO_SPEED_FREQ_LOW;
  HAL_GPIO_Init(GPIOA, &GPIO_InitStruct);

  /*Configure GPIO pin : TRIG_Pin */
  GPIO_InitStruct.Pin = TRIG_Pin;
  GPIO_InitStruct.Mode = GPIO_MODE_OUTPUT_PP;
  GPIO_InitStruct.Pull = GPIO_PULLDOWN;
  GPIO_InitStruct.Speed = GPIO_SPEED_FREQ_HIGH;
  HAL_GPIO_Init(TRIG_GPIO_Port, &GPIO_InitStruct);

  /*Configure GPIO pin : RS485_M2_TX_EN_Pin */
  GPIO_InitStruct.Pin = RS485_M2_TX_EN_Pin;
  GPIO_InitStruct.Mode = GPIO_MODE_OUTPUT_PP;
  GPIO_InitStruct.Pull = GPIO_NOPULL;
  GPIO_InitStruct.Speed = GPIO_SPEED_FREQ_HIGH;
  HAL_GPIO_Init(RS485_M2_TX_EN_GPIO_Port, &GPIO_InitStruct);

  /*Configure GPIO pin : RS485_M2_RX_LED_Pin */
  GPIO_InitStruct.Pin = RS485_M2_RX_LED_Pin;
  GPIO_InitStruct.Mode = GPIO_MODE_OUTPUT_PP;
  GPIO_InitStruct.Pull = GPIO_NOPULL;
  GPIO_InitStruct.Speed = GPIO_SPEED_FREQ_LOW;
  HAL_GPIO_Init(RS485_M2_RX_LED_GPIO_Port, &GPIO_InitStruct);

  /*Configure GPIO pin : RS485_M1_TX_EN_Pin */
  GPIO_InitStruct.Pin = RS485_M1_TX_EN_Pin;
  GPIO_InitStruct.Mode = GPIO_MODE_OUTPUT_PP;
  GPIO_InitStruct.Pull = GPIO_NOPULL;
  GPIO_InitStruct.Speed = GPIO_SPEED_FREQ_HIGH;
  HAL_GPIO_Init(RS485_M1_TX_EN_GPIO_Port, &GPIO_InitStruct);

  /*Configure GPIO pins : RS485_M1_RX_LED_Pin TURN_LED_RED_Pin TURN_LED_GREEN_Pin ORIENTATION_LED_RED_Pin
                           ORIENTATION_LED_GREEN_Pin ONTASK_LED_RED_Pin ONTASK_LED_GREEN_Pin LORA_RX_LED_Pin */
  GPIO_InitStruct.Pin = RS485_M1_RX_LED_Pin|TURN_LED_RED_Pin|TURN_LED_GREEN_Pin|ORIENTATION_LED_RED_Pin
                          |ORIENTATION_LED_GREEN_Pin|ONTASK_LED_RED_Pin|ONTASK_LED_GREEN_Pin|LORA_RX_LED_Pin;
  GPIO_InitStruct.Mode = GPIO_MODE_OUTPUT_PP;
  GPIO_InitStruct.Pull = GPIO_NOPULL;
  GPIO_InitStruct.Speed = GPIO_SPEED_FREQ_LOW;
  HAL_GPIO_Init(GPIOD, &GPIO_InitStruct);

  /*Configure GPIO pins : PG7 LORA_NSS_Pin LORA_RST_Pin LORA_TX_LED_Pin */
  GPIO_InitStruct.Pin = GPIO_PIN_7|LORA_NSS_Pin|LORA_RST_Pin|LORA_TX_LED_Pin;
  GPIO_InitStruct.Mode = GPIO_MODE_OUTPUT_PP;
  GPIO_InitStruct.Pull = GPIO_NOPULL;
  GPIO_InitStruct.Speed = GPIO_SPEED_FREQ_LOW;
  HAL_GPIO_Init(GPIOG, &GPIO_InitStruct);

  /*Configure GPIO pin : LORA_DIO0_Pin */
  GPIO_InitStruct.Pin = LORA_DIO0_Pin;
  GPIO_InitStruct.Mode = GPIO_MODE_IT_RISING;
  GPIO_InitStruct.Pull = GPIO_NOPULL;
  HAL_GPIO_Init(LORA_DIO0_GPIO_Port, &GPIO_InitStruct);

  /* EXTI interrupt init*/
  HAL_NVIC_SetPriority(EXTI0_IRQn, 0, 0);
  HAL_NVIC_EnableIRQ(EXTI0_IRQn);

  HAL_NVIC_SetPriority(EXTI1_IRQn, 0, 0);
  HAL_NVIC_EnableIRQ(EXTI1_IRQn);

  HAL_NVIC_SetPriority(EXTI2_IRQn, 0, 0);
  HAL_NVIC_EnableIRQ(EXTI2_IRQn);

  HAL_NVIC_SetPriority(EXTI3_IRQn, 0, 0);
  HAL_NVIC_EnableIRQ(EXTI3_IRQn);

  HAL_NVIC_SetPriority(EXTI15_10_IRQn, 0, 0);
  HAL_NVIC_EnableIRQ(EXTI15_10_IRQn);

}

void Error_Handler(void)
{
  __disable_irq();
  while (1)
  {
  }
}
